AUTOSAR XML (schema 4-1-3)
standard types defined: boolean, sint8, uint16, uint32, uint8, boolean_CompuMethod, boolean_DataConstr, sint8_DataConstr, uint16_DataConstr, uint32_DataConstr, uint8_DataConstr, sint16
package /MICROSAR/Dem_swc/DataTypes
  5 x impl type:
    Dem_DebounceResetStatusType: compu {0=DEM_DEBOUNCE_STATUS_FREEZE, 1=DEM_DEBOUNCE_STATUS_RESET}, range raw 0..255, implementation-data-type=ImplementationDataTypes/uint8
    Dem_DTCFormatType: compu {0=DEM_DTC_FORMAT_OBD, 1=DEM_DTC_FORMAT_UDS, 2=DEM_DTC_FORMAT_J1939}, range raw 0..255, implementation-data-type=ImplementationDataTypes/uint8
    Dem_EventStatusType:
      compu {0=DEM_EVENT_STATUS_PASSED, 1=DEM_EVENT_STATUS_FAILED, 2=DEM_EVENT_STATUS_PREPASSED, 3=DEM_EVENT_STATUS_PREFAILED, 4=DEM_EVENT_STATUS_FDC_THRESHOLD_REACHED, 5=DEM_EVENT_STATUS_PASSED_CONDITIONS_NOT_FULFILLED, 6=DEM_EVENT_STATUS_FAILED_CONDITIONS_NOT_FULFILLED, 7=DEM_EVENT_STATUS_PREPASSED_CONDITIONS_NOT_FULFILLED, 8=DEM_EVENT_STATUS_PREFAILED_CONDITIONS_NOT_FULFILLED}
      range raw 0..255
      implementation-data-type=ImplementationDataTypes/uint8
    Dem_MaxDataValueType: category=ARRAY, sw-calibration-access=READ-ONLY
      element Dem_MaxDataValueTypeElement: array-size=4, array-size-semantics=FIXED-SIZE, implementation-data-type=ImplementationDataTypes/uint8
    Dem_UdsStatusByteType:
      compu {mask 1: 1=DEM_UDS_STATUS_TF (bit 0: TestFailed), mask 2: 2=DEM_UDS_STATUS_TFTOC (bit 1: TestFailedThisOperationCycle), mask 4: 4=DEM_UDS_STATUS_PDTC (bit 2: PendingDTC), mask 8: 8=DEM_UDS_STATUS_CDTC (bit 3: ConfirmedDTC), mask 16: 16=DEM_UDS_STATUS_TNCSLC (bit 4: TestNotCompletedSinceLastClear), mask 32: 32=DEM_UDS_STATUS_TFSLC (bit 5: TestFailedSinceLastClear), mask 64: 64=DEM_UDS_STATUS_TNCTOC (bit 6: TestNotCompletedThisOperationCycle), mask 128: 128=DEM_UDS_STATUS_WIR (bit 7: WarningIndicatorRequested)}
      range raw 0..255
      implementation-data-type=ImplementationDataTypes/uint8
package /MICROSAR/Dem_swc/Interfaces
  client server interface DiagnosticMonitor: is-service=true, service-kind=DIAGNOSTIC-EVENT-MANAGER
    11 x operation:
      GetDTCOfEvent: possible-error=[DEM_E_NO_DTC_AVAILABLE, DiagnosticMonitor/E_NOT_OK]
        arg DTCFormat: type=Dem_DTCFormatType, direction=IN, server-argument-impl-policy=USE-ARGUMENT-TYPE
        arg DTCOfEvent: type=ImplementationDataTypes/uint32, direction=OUT, server-argument-impl-policy=USE-ARGUMENT-TYPE
      GetEventExtendedDataRecordEx: possible-error=[DEM_BUFFER_TOO_SMALL, DEM_NO_SUCH_ELEMENT, DiagnosticMonitor/E_NOT_OK]
        arg RecordNumber: type=ImplementationDataTypes/uint8, direction=IN, server-argument-impl-policy=USE-ARGUMENT-TYPE
        arg DestBuffer: type=Dem_MaxDataValueType, direction=OUT, server-argument-impl-policy=USE-ARGUMENT-TYPE
        arg BufSize: type=ImplementationDataTypes/uint16, direction=INOUT, server-argument-impl-policy=USE-ARGUMENT-TYPE
      GetEventFailed: possible-error=DiagnosticMonitor/E_NOT_OK
        arg EventFailed: type=ImplementationDataTypes/boolean, direction=OUT, server-argument-impl-policy=USE-ARGUMENT-TYPE
      GetEventFreezeFrameDataEx: possible-error=[DEM_BUFFER_TOO_SMALL, DEM_NO_SUCH_ELEMENT, DiagnosticMonitor/E_NOT_OK]
        4 x arg, all with server-argument-impl-policy=USE-ARGUMENT-TYPE:
          RecordNumber: type=ImplementationDataTypes/uint8, direction=IN
          DataId: type=ImplementationDataTypes/uint16, direction=IN
          DestBuffer: type=Dem_MaxDataValueType, direction=OUT
          BufSize: type=ImplementationDataTypes/uint16, direction=INOUT
      GetEventStatus: possible-error=DiagnosticMonitor/E_NOT_OK
        arg UDSStatusByte: type=Dem_UdsStatusByteType, direction=OUT, server-argument-impl-policy=USE-ARGUMENT-TYPE
      GetEventTested: possible-error=DiagnosticMonitor/E_NOT_OK
        arg EventTested: type=ImplementationDataTypes/boolean, direction=OUT, server-argument-impl-policy=USE-ARGUMENT-TYPE
      GetEventUdsStatus: possible-error=DiagnosticMonitor/E_NOT_OK
        arg UDSStatusByte: type=Dem_UdsStatusByteType, direction=OUT, server-argument-impl-policy=USE-ARGUMENT-TYPE
      GetFaultDetectionCounter: possible-error=[DEM_E_NO_FDC_AVAILABLE, DiagnosticMonitor/E_NOT_OK]
        arg FaultDetectionCounter: type=sint8, direction=OUT, server-argument-impl-policy=USE-ARGUMENT-TYPE
      ResetEventDebounceStatus: possible-error=DiagnosticMonitor/E_NOT_OK
        arg DebounceResetStatus: type=Dem_DebounceResetStatusType, direction=IN, server-argument-impl-policy=USE-ARGUMENT-TYPE
      ResetEventStatus: possible-error=DiagnosticMonitor/E_NOT_OK
      SetEventStatus: possible-error=DiagnosticMonitor/E_NOT_OK
        arg EventStatus: type=Dem_EventStatusType, direction=IN, server-argument-impl-policy=USE-ARGUMENT-TYPE
    5 x error:
      DEM_BUFFER_TOO_SMALL: error-code=21
      DEM_E_NO_DTC_AVAILABLE: error-code=10
      DEM_E_NO_FDC_AVAILABLE: error-code=14
      DEM_NO_SUCH_ELEMENT: error-code=48
      E_NOT_OK: error-code=1
package /UAES/ASW/CompuMethods
  compu method CM_boolean: 0=FALSE, 1=TRUE
package /UAES/ASW/DataConstrs
  range DC_boolean: raw 0..1
  range DC_sint16: raw -32768..32767
  range DC_uint16: raw 0..65535
  range DC_uint32: raw 0..4294967295
  range DC_uint8: raw 0..255
package /UAES/ASW/DataTypeMappingSets
  data type mapping set DTMS_Lock_DD
package /UAES/ASW/PortInterfaces
  5 x client server interface:
    IoHwAb_HbrModCtrl
      operation Hbr_SetMod: possible-error=IoHwAb_HbrModCtrl/E_NOT_OK
        arg id_u16: type=ImplementationDataTypes/uint16, direction=IN, server-argument-impl-policy=USE-ARGUMENT-TYPE
        arg mod_u8: type=ImplementationDataTypes/uint8, direction=IN, server-argument-impl-policy=USE-ARGUMENT-TYPE
      error E_NOT_OK: error-code=1
    IoHwAb_HbrPwm
      operation Hbr_SetDuty: possible-error=IoHwAb_HbrPwm/E_NOT_OK
        arg id_u16: type=ImplementationDataTypes/uint16, direction=IN, server-argument-impl-policy=USE-ARGUMENT-TYPE
        arg duty_u16: type=ImplementationDataTypes/uint16, direction=IN, server-argument-impl-policy=USE-ARGUMENT-TYPE
      operation Hbr_SetPerd: possible-error=IoHwAb_HbrPwm/E_NOT_OK
        arg id_u16: type=ImplementationDataTypes/uint16, direction=IN, server-argument-impl-policy=USE-ARGUMENT-TYPE
        arg perd_u32: type=ImplementationDataTypes/uint32, direction=IN, server-argument-impl-policy=USE-ARGUMENT-TYPE
      operation Hbr_SetPerdAndDuty: possible-error=IoHwAb_HbrPwm/E_NOT_OK
        arg id_u16: type=ImplementationDataTypes/uint16, direction=IN, server-argument-impl-policy=USE-ARGUMENT-TYPE
        arg perd_u32: type=ImplementationDataTypes/uint32, direction=IN, server-argument-impl-policy=USE-ARGUMENT-TYPE
        arg duty_u16: type=ImplementationDataTypes/uint16, direction=IN, server-argument-impl-policy=USE-ARGUMENT-TYPE
      error E_NOT_OK: error-code=1
    IoHwAb_IoDiagHbr
      operation Hbr_Get: possible-error=IoHwAb_IoDiagHbr/E_NOT_OK
        arg id_u16: type=ImplementationDataTypes/uint16, direction=IN, server-argument-impl-policy=USE-ARGUMENT-TYPE
        arg val_u32: type=ImplementationDataTypes/uint32, direction=OUT, server-argument-impl-policy=USE-ARGUMENT-TYPE
      error E_NOT_OK: error-code=1
    IoHwAb_IoSigAdc
      operation Adc_Get: possible-error=IoHwAb_IoSigAdc/E_NOT_OK
        arg id_u16: type=ImplementationDataTypes/uint16, direction=IN, server-argument-impl-policy=USE-ARGUMENT-TYPE
        arg val_s16: type=sint16, direction=OUT, server-argument-impl-policy=USE-ARGUMENT-TYPE
      operation AdcFac_Get: possible-error=IoHwAb_IoSigAdc/E_NOT_OK
        arg id_u16: type=ImplementationDataTypes/uint16, direction=IN, server-argument-impl-policy=USE-ARGUMENT-TYPE
        arg val_s16: type=sint16, direction=OUT, server-argument-impl-policy=USE-ARGUMENT-TYPE
      operation AdcVRMBatt_Get: possible-error=IoHwAb_IoSigAdc/E_NOT_OK
        arg id_u16: type=ImplementationDataTypes/uint16, direction=IN, server-argument-impl-policy=USE-ARGUMENT-TYPE
        arg val_u8: type=ImplementationDataTypes/uint8, direction=OUT, server-argument-impl-policy=USE-ARGUMENT-TYPE
      error E_NOT_OK: error-code=1
    IoHwAb_IoSigDio
      operation Di_Get: possible-error=IoHwAb_IoSigDio/E_NOT_OK
        arg id_u16: type=ImplementationDataTypes/uint16, direction=IN, server-argument-impl-policy=USE-ARGUMENT-TYPE
        arg val_u8: type=ImplementationDataTypes/uint8, direction=OUT, server-argument-impl-policy=USE-ARGUMENT-TYPE
      operation Do_Set: possible-error=IoHwAb_IoSigDio/E_NOT_OK
        arg id_u16: type=ImplementationDataTypes/uint16, direction=IN, server-argument-impl-policy=USE-ARGUMENT-TYPE
        arg val_u8: type=ImplementationDataTypes/uint8, direction=IN, server-argument-impl-policy=USE-ARGUMENT-TYPE
      error E_NOT_OK: error-code=1
  62 x sender receiver interface:
    gHoodLock_bLockCmdTrigUds: invalidation-policy{data-element=gHoodLock_bLockCmdTrigUds/Val, handle-invalid=DONT-INVALIDATE}
      data Val: sw-calibration-access=READ-ONLY, type=ImplementationDataTypes/boolean
    gHoodLock_u8LockCmd: invalidation-policy{data-element=gHoodLock_u8LockCmd/Val, handle-invalid=DONT-INVALIDATE}
      data Val: sw-calibration-access=READ-ONLY, type=ImplementationDataTypes/uint8
    gHoodLock_u8LockCmdUds: invalidation-policy{data-element=gHoodLock_u8LockCmdUds/Val, handle-invalid=DONT-INVALIDATE}
      data Val: sw-calibration-access=READ-ONLY, type=ImplementationDataTypes/uint8
    gLock_bChrgCapSwt: invalidation-policy{data-element=gLock_bChrgCapSwt/Val, handle-invalid=DONT-INVALIDATE}
      data Val: sw-calibration-access=READ-ONLY, type=ImplementationDataTypes/boolean
    gLock_bDrvChrgCapUnlockSwt: invalidation-policy{data-element=gLock_bDrvChrgCapUnlockSwt/Val, handle-invalid=DONT-INVALIDATE}
      data Val: sw-calibration-access=READ-ONLY, type=ImplementationDataTypes/boolean
    gLock_bExtTrunkUnlockSwt: invalidation-policy{data-element=gLock_bExtTrunkUnlockSwt/Val, handle-invalid=DONT-INVALIDATE}
      data Val: sw-calibration-access=READ-ONLY, type=ImplementationDataTypes/boolean
    gLock_bFLDoorLockFbSt: invalidation-policy{data-element=gLock_bFLDoorLockFbSt/Val, handle-invalid=DONT-INVALIDATE}
      data Val: sw-calibration-access=READ-ONLY, type=ImplementationDataTypes/boolean
    gLock_bFLPwrRelsMotorMinusSt: invalidation-policy{data-element=gLock_bFLPwrRelsMotorMinusSt/Val, handle-invalid=DONT-INVALIDATE}
      data Val: sw-calibration-access=READ-ONLY, type=ImplementationDataTypes/boolean
    gLock_bFLPwrRelsMotorPlusSt: invalidation-policy{data-element=gLock_bFLPwrRelsMotorPlusSt/Val, handle-invalid=DONT-INVALIDATE}
      data Val: sw-calibration-access=READ-ONLY, type=ImplementationDataTypes/boolean
    gLock_bFRDoorLockFbSt: invalidation-policy{data-element=gLock_bFRDoorLockFbSt/Val, handle-invalid=DONT-INVALIDATE}
      data Val: sw-calibration-access=READ-ONLY, type=ImplementationDataTypes/boolean
    gLock_bFRPwrRelsMotorMinusSt: invalidation-policy{data-element=gLock_bFRPwrRelsMotorMinusSt/Val, handle-invalid=DONT-INVALIDATE}
      data Val: sw-calibration-access=READ-ONLY, type=ImplementationDataTypes/boolean
    gLock_bFRPwrRelsMotorPlusSt: invalidation-policy{data-element=gLock_bFRPwrRelsMotorPlusSt/Val, handle-invalid=DONT-INVALIDATE}
      data Val: sw-calibration-access=READ-ONLY, type=ImplementationDataTypes/boolean
    gLock_bHoodUnlockSwt: invalidation-policy{data-element=gLock_bHoodUnlockSwt/Val, handle-invalid=DONT-INVALIDATE}
      data Val: sw-calibration-access=READ-ONLY, type=ImplementationDataTypes/boolean
    gLock_bIntTrunkUnlockSwt: invalidation-policy{data-element=gLock_bIntTrunkUnlockSwt/Val, handle-invalid=DONT-INVALIDATE}
      data Val: sw-calibration-access=READ-ONLY, type=ImplementationDataTypes/boolean
    gLock_bMasterDrvLockSwt: invalidation-policy{data-element=gLock_bMasterDrvLockSwt/Val, handle-invalid=DONT-INVALIDATE}
      data Val: sw-calibration-access=READ-ONLY, type=ImplementationDataTypes/boolean
    gLock_bMasterLockSwt: invalidation-policy{data-element=gLock_bMasterLockSwt/Val, handle-invalid=DONT-INVALIDATE}
      data Val: sw-calibration-access=READ-ONLY, type=ImplementationDataTypes/boolean
    gLock_bMasterPsgLockSwt: invalidation-policy{data-element=gLock_bMasterPsgLockSwt/Val, handle-invalid=DONT-INVALIDATE}
      data Val: sw-calibration-access=READ-ONLY, type=ImplementationDataTypes/boolean
    gLock_bMasterUnlockSwt: invalidation-policy{data-element=gLock_bMasterUnlockSwt/Val, handle-invalid=DONT-INVALIDATE}
      data Val: sw-calibration-access=READ-ONLY, type=ImplementationDataTypes/boolean
    gLock_bMechKeyLockSwt: invalidation-policy{data-element=gLock_bMechKeyLockSwt/Val, handle-invalid=DONT-INVALIDATE}
      data Val: sw-calibration-access=READ-ONLY, type=ImplementationDataTypes/boolean
    gLock_bMechKeyUnlockSwt: invalidation-policy{data-element=gLock_bMechKeyUnlockSwt/Val, handle-invalid=DONT-INVALIDATE}
      data Val: sw-calibration-access=READ-ONLY, type=ImplementationDataTypes/boolean
    gLock_bRLChildLockFbSt: invalidation-policy{data-element=gLock_bRLChildLockFbSt/Val, handle-invalid=DONT-INVALIDATE}
      data Val: sw-calibration-access=READ-ONLY, type=ImplementationDataTypes/boolean
    gLock_bRLDoorLockFbSt: invalidation-policy{data-element=gLock_bRLDoorLockFbSt/Val, handle-invalid=DONT-INVALIDATE}
      data Val: sw-calibration-access=READ-ONLY, type=ImplementationDataTypes/boolean
    gLock_bRLPwrRelsMotorMinusSt: invalidation-policy{data-element=gLock_bRLPwrRelsMotorMinusSt/Val, handle-invalid=DONT-INVALIDATE}
      data Val: sw-calibration-access=READ-ONLY, type=ImplementationDataTypes/boolean
    gLock_bRLPwrRelsMotorPlusSt: invalidation-policy{data-element=gLock_bRLPwrRelsMotorPlusSt/Val, handle-invalid=DONT-INVALIDATE}
      data Val: sw-calibration-access=READ-ONLY, type=ImplementationDataTypes/boolean
    gLock_bRRChildLockFbSt: invalidation-policy{data-element=gLock_bRRChildLockFbSt/Val, handle-invalid=DONT-INVALIDATE}
      data Val: sw-calibration-access=READ-ONLY, type=ImplementationDataTypes/boolean
    gLock_bRRDoorLockFbSt: invalidation-policy{data-element=gLock_bRRDoorLockFbSt/Val, handle-invalid=DONT-INVALIDATE}
      data Val: sw-calibration-access=READ-ONLY, type=ImplementationDataTypes/boolean
    gLock_bRRPwrRelsMotorMinusSt: invalidation-policy{data-element=gLock_bRRPwrRelsMotorMinusSt/Val, handle-invalid=DONT-INVALIDATE}
      data Val: sw-calibration-access=READ-ONLY, type=ImplementationDataTypes/boolean
    gLock_bRRPwrRelsMotorPlusSt: invalidation-policy{data-element=gLock_bRRPwrRelsMotorPlusSt/Val, handle-invalid=DONT-INVALIDATE}
      data Val: sw-calibration-access=READ-ONLY, type=ImplementationDataTypes/boolean
    gLock_u16ChrgCapPosVolt: invalidation-policy{data-element=gLock_u16ChrgCapPosVolt/Val, handle-invalid=DONT-INVALIDATE}
      data Val: sw-calibration-access=READ-ONLY, type=ImplementationDataTypes/uint16
    gLock_u8BootLockMotorPs: invalidation-policy{data-element=gLock_u8BootLockMotorPs/Val, handle-invalid=DONT-INVALIDATE}
      data Val: sw-calibration-access=READ-ONLY, type=ImplementationDataTypes/uint8
    gLock_u8ChrgCapLockMotorPs: invalidation-policy{data-element=gLock_u8ChrgCapLockMotorPs/Val, handle-invalid=DONT-INVALIDATE}
      data Val: sw-calibration-access=READ-ONLY, type=ImplementationDataTypes/uint8
    gLock_u8DiagEnbCnd: invalidation-policy{data-element=gLock_u8DiagEnbCnd/Val, handle-invalid=DONT-INVALIDATE}
      data Val: sw-calibration-access=READ-ONLY, type=ImplementationDataTypes/uint8
    gLock_u8FLDoorLockMotorPs: invalidation-policy{data-element=gLock_u8FLDoorLockMotorPs/Val, handle-invalid=DONT-INVALIDATE}
      data Val: sw-calibration-access=READ-ONLY, type=ImplementationDataTypes/uint8
    gLock_u8FLPwrRelsMotorPs: invalidation-policy{data-element=gLock_u8FLPwrRelsMotorPs/Val, handle-invalid=DONT-INVALIDATE}
      data Val: sw-calibration-access=READ-ONLY, type=ImplementationDataTypes/uint8
    gLock_u8FRDoorLockMotorPs: invalidation-policy{data-element=gLock_u8FRDoorLockMotorPs/Val, handle-invalid=DONT-INVALIDATE}
      data Val: sw-calibration-access=READ-ONLY, type=ImplementationDataTypes/uint8
    gLock_u8FRPwrRelsMotorPs: invalidation-policy{data-element=gLock_u8FRPwrRelsMotorPs/Val, handle-invalid=DONT-INVALIDATE}
      data Val: sw-calibration-access=READ-ONLY, type=ImplementationDataTypes/uint8
    gLock_u8GlcBoxLockMotorPs: invalidation-policy{data-element=gLock_u8GlcBoxLockMotorPs/Val, handle-invalid=DONT-INVALIDATE}
      data Val: sw-calibration-access=READ-ONLY, type=ImplementationDataTypes/uint8
    gLock_u8OilTankLockMotorPs: invalidation-policy{data-element=gLock_u8OilTankLockMotorPs/Val, handle-invalid=DONT-INVALIDATE}
      data Val: sw-calibration-access=READ-ONLY, type=ImplementationDataTypes/uint8
    gLock_u8RLChildLockMotorPs: invalidation-policy{data-element=gLock_u8RLChildLockMotorPs/Val, handle-invalid=DONT-INVALIDATE}
      data Val: sw-calibration-access=READ-ONLY, type=ImplementationDataTypes/uint8
    gLock_u8RLDoorLockMotorPs: invalidation-policy{data-element=gLock_u8RLDoorLockMotorPs/Val, handle-invalid=DONT-INVALIDATE}
      data Val: sw-calibration-access=READ-ONLY, type=ImplementationDataTypes/uint8
    gLock_u8RLPwrRelsMotorPs: invalidation-policy{data-element=gLock_u8RLPwrRelsMotorPs/Val, handle-invalid=DONT-INVALIDATE}
      data Val: sw-calibration-access=READ-ONLY, type=ImplementationDataTypes/uint8
    gLock_u8RRChildLockMotorPs: invalidation-policy{data-element=gLock_u8RRChildLockMotorPs/Val, handle-invalid=DONT-INVALIDATE}
      data Val: sw-calibration-access=READ-ONLY, type=ImplementationDataTypes/uint8
    gLock_u8RRDoorLockMotorPs: invalidation-policy{data-element=gLock_u8RRDoorLockMotorPs/Val, handle-invalid=DONT-INVALIDATE}
      data Val: sw-calibration-access=READ-ONLY, type=ImplementationDataTypes/uint8
    gLock_u8RRPwrRelsMotorPs: invalidation-policy{data-element=gLock_u8RRPwrRelsMotorPs/Val, handle-invalid=DONT-INVALIDATE}
      data Val: sw-calibration-access=READ-ONLY, type=ImplementationDataTypes/uint8
    gLockCtrl_u8BootLockMotorOutput: invalidation-policy{data-element=gLockCtrl_u8BootLockMotorOutput/Val, handle-invalid=DONT-INVALIDATE}
      data Val: sw-calibration-access=READ-ONLY, type=ImplementationDataTypes/uint8
    gLockCtrl_u8ChrgCapLockMotorOutput: invalidation-policy{data-element=gLockCtrl_u8ChrgCapLockMotorOutput/Val, handle-invalid=DONT-INVALIDATE}
      data Val: sw-calibration-access=READ-ONLY, type=ImplementationDataTypes/uint8
    gLockCtrl_u8ElectcGlvBoxLockMotorOutput: invalidation-policy{data-element=gLockCtrl_u8ElectcGlvBoxLockMotorOutput/Val, handle-invalid=DONT-INVALIDATE}
      data Val: sw-calibration-access=READ-ONLY, type=ImplementationDataTypes/uint8
    gLockCtrl_u8FLDoorElecRelMotorOutput: invalidation-policy{data-element=gLockCtrl_u8FLDoorElecRelMotorOutput/Val, handle-invalid=DONT-INVALIDATE}
      data Val: sw-calibration-access=READ-ONLY, type=ImplementationDataTypes/uint8
    gLockCtrl_u8FLDoorElecRelResetMotorOutput: invalidation-policy{data-element=gLockCtrl_u8FLDoorElecRelResetMotorOutput/Val, handle-invalid=DONT-INVALIDATE}
      data Val: sw-calibration-access=READ-ONLY, type=ImplementationDataTypes/uint8
    gLockCtrl_u8FLDoorLockMotorOutput: invalidation-policy{data-element=gLockCtrl_u8FLDoorLockMotorOutput/Val, handle-invalid=DONT-INVALIDATE}
      data Val: sw-calibration-access=READ-ONLY, type=ImplementationDataTypes/uint8
    gLockCtrl_u8FRDoorLockMotorOutput: invalidation-policy{data-element=gLockCtrl_u8FRDoorLockMotorOutput/Val, handle-invalid=DONT-INVALIDATE}
      data Val: sw-calibration-access=READ-ONLY, type=ImplementationDataTypes/uint8
    gLockCtrl_u8FRElecRelMotorOutput: invalidation-policy{data-element=gLockCtrl_u8FRElecRelMotorOutput/Val, handle-invalid=DONT-INVALIDATE}
      data Val: sw-calibration-access=READ-ONLY, type=ImplementationDataTypes/uint8
    gLockCtrl_u8FRElecRelResetMotorOutput: invalidation-policy{data-element=gLockCtrl_u8FRElecRelResetMotorOutput/Val, handle-invalid=DONT-INVALIDATE}
      data Val: sw-calibration-access=READ-ONLY, type=ImplementationDataTypes/uint8
    gLockCtrl_u8OilTankLockMotorOutput: invalidation-policy{data-element=gLockCtrl_u8OilTankLockMotorOutput/Val, handle-invalid=DONT-INVALIDATE}
      data Val: sw-calibration-access=READ-ONLY, type=ImplementationDataTypes/uint8
    gLockCtrl_u8RLChildLockMotorOutput: invalidation-policy{data-element=gLockCtrl_u8RLChildLockMotorOutput/Val, handle-invalid=DONT-INVALIDATE}
      data Val: sw-calibration-access=READ-ONLY, type=ImplementationDataTypes/uint8
    gLockCtrl_u8RLDoorElecRelMotorOutput: invalidation-policy{data-element=gLockCtrl_u8RLDoorElecRelMotorOutput/Val, handle-invalid=DONT-INVALIDATE}
      data Val: sw-calibration-access=READ-ONLY, type=ImplementationDataTypes/uint8
    gLockCtrl_u8RLDoorElecRelPWMMotorOutput: invalidation-policy{data-element=gLockCtrl_u8RLDoorElecRelPWMMotorOutput/Val, handle-invalid=DONT-INVALIDATE}
      data Val: sw-calibration-access=READ-ONLY, type=ImplementationDataTypes/uint8
    gLockCtrl_u8RLDoorLockMotorOutput: invalidation-policy{data-element=gLockCtrl_u8RLDoorLockMotorOutput/Val, handle-invalid=DONT-INVALIDATE}
      data Val: sw-calibration-access=READ-ONLY, type=ImplementationDataTypes/uint8
    gLockCtrl_u8RRChildLockMotorOutput: invalidation-policy{data-element=gLockCtrl_u8RRChildLockMotorOutput/Val, handle-invalid=DONT-INVALIDATE}
      data Val: sw-calibration-access=READ-ONLY, type=ImplementationDataTypes/uint8
    gLockCtrl_u8RRDoorElecRelMotorOutput: invalidation-policy{data-element=gLockCtrl_u8RRDoorElecRelMotorOutput/Val, handle-invalid=DONT-INVALIDATE}
      data Val: sw-calibration-access=READ-ONLY, type=ImplementationDataTypes/uint8
    gLockCtrl_u8RRDoorElecRelPWMMotorOutput: invalidation-policy{data-element=gLockCtrl_u8RRDoorElecRelPWMMotorOutput/Val, handle-invalid=DONT-INVALIDATE}
      data Val: sw-calibration-access=READ-ONLY, type=ImplementationDataTypes/uint8
    gLockCtrl_u8RRDoorLockMotorOutput: invalidation-policy{data-element=gLockCtrl_u8RRDoorLockMotorOutput/Val, handle-invalid=DONT-INVALIDATE}
      data Val: sw-calibration-access=READ-ONLY, type=ImplementationDataTypes/uint8
package /UAES/ASW/SwComponentTypes
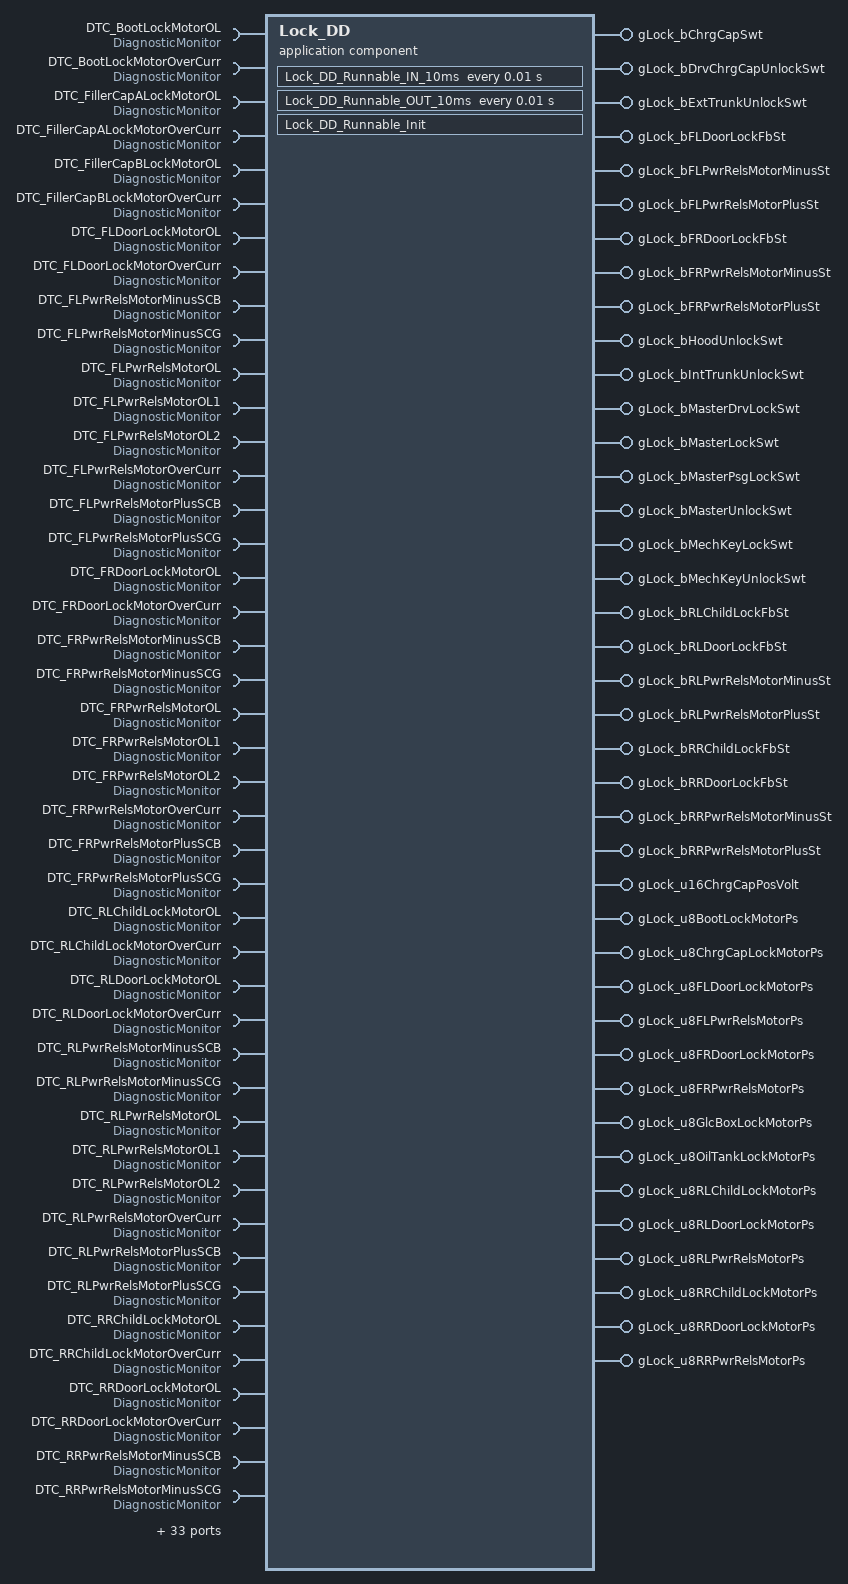
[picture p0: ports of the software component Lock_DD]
  application sw component type Lock_DD
    40 x provide port:
      gLock_bChrgCapSwt: nonqueued-sender-com-spec{data-element=gLock_bChrgCapSwt/Val, init-value=0}, provided-interface=gLock_bChrgCapSwt
      gLock_bDrvChrgCapUnlockSwt: nonqueued-sender-com-spec{data-element=gLock_bDrvChrgCapUnlockSwt/Val, init-value=0}, provided-interface=gLock_bDrvChrgCapUnlockSwt
      gLock_bExtTrunkUnlockSwt: nonqueued-sender-com-spec{data-element=gLock_bExtTrunkUnlockSwt/Val, init-value=0}, provided-interface=gLock_bExtTrunkUnlockSwt
      gLock_bFLDoorLockFbSt: nonqueued-sender-com-spec{data-element=gLock_bFLDoorLockFbSt/Val, init-value=0}, provided-interface=gLock_bFLDoorLockFbSt
      gLock_bFLPwrRelsMotorMinusSt: nonqueued-sender-com-spec{data-element=gLock_bFLPwrRelsMotorMinusSt/Val, init-value=0}, provided-interface=gLock_bFLPwrRelsMotorMinusSt
      gLock_bFLPwrRelsMotorPlusSt: nonqueued-sender-com-spec{data-element=gLock_bFLPwrRelsMotorPlusSt/Val, init-value=0}, provided-interface=gLock_bFLPwrRelsMotorPlusSt
      gLock_bFRDoorLockFbSt: nonqueued-sender-com-spec{data-element=gLock_bFRDoorLockFbSt/Val, init-value=0}, provided-interface=gLock_bFRDoorLockFbSt
      gLock_bFRPwrRelsMotorMinusSt: nonqueued-sender-com-spec{data-element=gLock_bFRPwrRelsMotorMinusSt/Val, init-value=0}, provided-interface=gLock_bFRPwrRelsMotorMinusSt
      gLock_bFRPwrRelsMotorPlusSt: nonqueued-sender-com-spec{data-element=gLock_bFRPwrRelsMotorPlusSt/Val, init-value=0}, provided-interface=gLock_bFRPwrRelsMotorPlusSt
      gLock_bHoodUnlockSwt: nonqueued-sender-com-spec{data-element=gLock_bHoodUnlockSwt/Val, init-value=0}, provided-interface=gLock_bHoodUnlockSwt
      gLock_bIntTrunkUnlockSwt: nonqueued-sender-com-spec{data-element=gLock_bIntTrunkUnlockSwt/Val, init-value=0}, provided-interface=gLock_bIntTrunkUnlockSwt
      gLock_bMasterDrvLockSwt: nonqueued-sender-com-spec{data-element=gLock_bMasterDrvLockSwt/Val, init-value=0}, provided-interface=gLock_bMasterDrvLockSwt
      gLock_bMasterLockSwt: nonqueued-sender-com-spec{data-element=gLock_bMasterLockSwt/Val, init-value=0}, provided-interface=gLock_bMasterLockSwt
      gLock_bMasterPsgLockSwt: nonqueued-sender-com-spec{data-element=gLock_bMasterPsgLockSwt/Val, init-value=0}, provided-interface=gLock_bMasterPsgLockSwt
      gLock_bMasterUnlockSwt: nonqueued-sender-com-spec{data-element=gLock_bMasterUnlockSwt/Val, init-value=0}, provided-interface=gLock_bMasterUnlockSwt
      gLock_bMechKeyLockSwt: nonqueued-sender-com-spec{data-element=gLock_bMechKeyLockSwt/Val, init-value=0}, provided-interface=gLock_bMechKeyLockSwt
      gLock_bMechKeyUnlockSwt: nonqueued-sender-com-spec{data-element=gLock_bMechKeyUnlockSwt/Val, init-value=0}, provided-interface=gLock_bMechKeyUnlockSwt
      gLock_bRLChildLockFbSt: nonqueued-sender-com-spec{data-element=gLock_bRLChildLockFbSt/Val, init-value=0}, provided-interface=gLock_bRLChildLockFbSt
      gLock_bRLDoorLockFbSt: nonqueued-sender-com-spec{data-element=gLock_bRLDoorLockFbSt/Val, init-value=0}, provided-interface=gLock_bRLDoorLockFbSt
      gLock_bRLPwrRelsMotorMinusSt: nonqueued-sender-com-spec{data-element=gLock_bRLPwrRelsMotorMinusSt/Val, init-value=0}, provided-interface=gLock_bRLPwrRelsMotorMinusSt
      gLock_bRLPwrRelsMotorPlusSt: nonqueued-sender-com-spec{data-element=gLock_bRLPwrRelsMotorPlusSt/Val, init-value=0}, provided-interface=gLock_bRLPwrRelsMotorPlusSt
      gLock_bRRChildLockFbSt: nonqueued-sender-com-spec{data-element=gLock_bRRChildLockFbSt/Val, init-value=0}, provided-interface=gLock_bRRChildLockFbSt
      gLock_bRRDoorLockFbSt: nonqueued-sender-com-spec{data-element=gLock_bRRDoorLockFbSt/Val, init-value=0}, provided-interface=gLock_bRRDoorLockFbSt
      gLock_bRRPwrRelsMotorMinusSt: nonqueued-sender-com-spec{data-element=gLock_bRRPwrRelsMotorMinusSt/Val, init-value=0}, provided-interface=gLock_bRRPwrRelsMotorMinusSt
      gLock_bRRPwrRelsMotorPlusSt: nonqueued-sender-com-spec{data-element=gLock_bRRPwrRelsMotorPlusSt/Val, init-value=0}, provided-interface=gLock_bRRPwrRelsMotorPlusSt
      gLock_u16ChrgCapPosVolt: nonqueued-sender-com-spec{data-element=gLock_u16ChrgCapPosVolt/Val, init-value=0}, provided-interface=gLock_u16ChrgCapPosVolt
      gLock_u8BootLockMotorPs: nonqueued-sender-com-spec{data-element=gLock_u8BootLockMotorPs/Val, init-value=0}, provided-interface=gLock_u8BootLockMotorPs
      gLock_u8ChrgCapLockMotorPs: nonqueued-sender-com-spec{data-element=gLock_u8ChrgCapLockMotorPs/Val, init-value=0}, provided-interface=gLock_u8ChrgCapLockMotorPs
      gLock_u8FLDoorLockMotorPs: nonqueued-sender-com-spec{data-element=gLock_u8FLDoorLockMotorPs/Val, init-value=0}, provided-interface=gLock_u8FLDoorLockMotorPs
      gLock_u8FLPwrRelsMotorPs: nonqueued-sender-com-spec{data-element=gLock_u8FLPwrRelsMotorPs/Val, init-value=0}, provided-interface=gLock_u8FLPwrRelsMotorPs
      gLock_u8FRDoorLockMotorPs: nonqueued-sender-com-spec{data-element=gLock_u8FRDoorLockMotorPs/Val, init-value=0}, provided-interface=gLock_u8FRDoorLockMotorPs
      gLock_u8FRPwrRelsMotorPs: nonqueued-sender-com-spec{data-element=gLock_u8FRPwrRelsMotorPs/Val, init-value=0}, provided-interface=gLock_u8FRPwrRelsMotorPs
      gLock_u8GlcBoxLockMotorPs: nonqueued-sender-com-spec{data-element=gLock_u8GlcBoxLockMotorPs/Val, init-value=0}, provided-interface=gLock_u8GlcBoxLockMotorPs
      gLock_u8OilTankLockMotorPs: nonqueued-sender-com-spec{data-element=gLock_u8OilTankLockMotorPs/Val, init-value=0}, provided-interface=gLock_u8OilTankLockMotorPs
      gLock_u8RLChildLockMotorPs: nonqueued-sender-com-spec{data-element=gLock_u8RLChildLockMotorPs/Val, init-value=0}, provided-interface=gLock_u8RLChildLockMotorPs
      gLock_u8RLDoorLockMotorPs: nonqueued-sender-com-spec{data-element=gLock_u8RLDoorLockMotorPs/Val, init-value=0}, provided-interface=gLock_u8RLDoorLockMotorPs
      gLock_u8RLPwrRelsMotorPs: nonqueued-sender-com-spec{data-element=gLock_u8RLPwrRelsMotorPs/Val, init-value=0}, provided-interface=gLock_u8RLPwrRelsMotorPs
      gLock_u8RRChildLockMotorPs: nonqueued-sender-com-spec{data-element=gLock_u8RRChildLockMotorPs/Val, init-value=0}, provided-interface=gLock_u8RRChildLockMotorPs
      gLock_u8RRDoorLockMotorPs: nonqueued-sender-com-spec{data-element=gLock_u8RRDoorLockMotorPs/Val, init-value=0}, provided-interface=gLock_u8RRDoorLockMotorPs
      gLock_u8RRPwrRelsMotorPs: nonqueued-sender-com-spec{data-element=gLock_u8RRPwrRelsMotorPs/Val, init-value=0}, provided-interface=gLock_u8RRPwrRelsMotorPs
    77 x require port:
      DTC_BootLockMotorOL: required-interface=DiagnosticMonitor
        required-com-specs:
          GetDTCOfEvent
          GetEventExtendedDataRecordEx
          GetEventFailed
          GetEventFreezeFrameDataEx
          GetEventStatus
          GetEventTested
          GetEventUdsStatus
          GetFaultDetectionCounter
          ResetEventDebounceStatus
          ResetEventStatus
          SetEventStatus
      DTC_BootLockMotorOverCurr: required-interface=DiagnosticMonitor
        required-com-specs:
          GetDTCOfEvent
          GetEventExtendedDataRecordEx
          GetEventFailed
          GetEventFreezeFrameDataEx
          GetEventStatus
          GetEventTested
          GetEventUdsStatus
          GetFaultDetectionCounter
          ResetEventDebounceStatus
          ResetEventStatus
          SetEventStatus
      DTC_FillerCapALockMotorOL: required-interface=DiagnosticMonitor
        required-com-specs:
          GetDTCOfEvent
          GetEventExtendedDataRecordEx
          GetEventFailed
          GetEventFreezeFrameDataEx
          GetEventStatus
          GetEventTested
          GetEventUdsStatus
          GetFaultDetectionCounter
          ResetEventDebounceStatus
          ResetEventStatus
          SetEventStatus
      DTC_FillerCapALockMotorOverCurr: required-interface=DiagnosticMonitor
        required-com-specs:
          GetDTCOfEvent
          GetEventExtendedDataRecordEx
          GetEventFailed
          GetEventFreezeFrameDataEx
          GetEventStatus
          GetEventTested
          GetEventUdsStatus
          GetFaultDetectionCounter
          ResetEventDebounceStatus
          ResetEventStatus
          SetEventStatus
      DTC_FillerCapBLockMotorOL: required-interface=DiagnosticMonitor
        required-com-specs:
          GetDTCOfEvent
          GetEventExtendedDataRecordEx
          GetEventFailed
          GetEventFreezeFrameDataEx
          GetEventStatus
          GetEventTested
          GetEventUdsStatus
          GetFaultDetectionCounter
          ResetEventDebounceStatus
          ResetEventStatus
          SetEventStatus
      DTC_FillerCapBLockMotorOverCurr: required-interface=DiagnosticMonitor
        required-com-specs:
          GetDTCOfEvent
          GetEventExtendedDataRecordEx
          GetEventFailed
          GetEventFreezeFrameDataEx
          GetEventStatus
          GetEventTested
          GetEventUdsStatus
          GetFaultDetectionCounter
          ResetEventDebounceStatus
          ResetEventStatus
          SetEventStatus
      DTC_FLDoorLockMotorOL: required-interface=DiagnosticMonitor
        required-com-specs:
          GetDTCOfEvent
          GetEventExtendedDataRecordEx
          GetEventFailed
          GetEventFreezeFrameDataEx
          GetEventStatus
          GetEventTested
          GetEventUdsStatus
          GetFaultDetectionCounter
          ResetEventDebounceStatus
          ResetEventStatus
          SetEventStatus
      DTC_FLDoorLockMotorOverCurr: required-interface=DiagnosticMonitor
        required-com-specs:
          GetDTCOfEvent
          GetEventExtendedDataRecordEx
          GetEventFailed
          GetEventFreezeFrameDataEx
          GetEventStatus
          GetEventTested
          GetEventUdsStatus
          GetFaultDetectionCounter
          ResetEventDebounceStatus
          ResetEventStatus
          SetEventStatus
      DTC_FLPwrRelsMotorMinusSCB: required-interface=DiagnosticMonitor
        required-com-specs:
          GetDTCOfEvent
          GetEventExtendedDataRecordEx
          GetEventFailed
          GetEventFreezeFrameDataEx
          GetEventStatus
          GetEventTested
          GetEventUdsStatus
          GetFaultDetectionCounter
          ResetEventDebounceStatus
          ResetEventStatus
          SetEventStatus
      DTC_FLPwrRelsMotorMinusSCG: required-interface=DiagnosticMonitor
        required-com-specs:
          GetDTCOfEvent
          GetEventExtendedDataRecordEx
          GetEventFailed
          GetEventFreezeFrameDataEx
          GetEventStatus
          GetEventTested
          GetEventUdsStatus
          GetFaultDetectionCounter
          ResetEventDebounceStatus
          ResetEventStatus
          SetEventStatus
      DTC_FLPwrRelsMotorOL: required-interface=DiagnosticMonitor
        required-com-specs:
          GetDTCOfEvent
          GetEventExtendedDataRecordEx
          GetEventFailed
          GetEventFreezeFrameDataEx
          GetEventStatus
          GetEventTested
          GetEventUdsStatus
          GetFaultDetectionCounter
          ResetEventDebounceStatus
          ResetEventStatus
          SetEventStatus
      DTC_FLPwrRelsMotorOL1: required-interface=DiagnosticMonitor
        required-com-specs:
          GetDTCOfEvent
          GetEventExtendedDataRecordEx
          GetEventFailed
          GetEventFreezeFrameDataEx
          GetEventStatus
          GetEventTested
          GetEventUdsStatus
          GetFaultDetectionCounter
          ResetEventDebounceStatus
          ResetEventStatus
          SetEventStatus
      DTC_FLPwrRelsMotorOL2: required-interface=DiagnosticMonitor
        required-com-specs:
          GetDTCOfEvent
          GetEventExtendedDataRecordEx
          GetEventFailed
          GetEventFreezeFrameDataEx
          GetEventStatus
          GetEventTested
          GetEventUdsStatus
          GetFaultDetectionCounter
          ResetEventDebounceStatus
          ResetEventStatus
          SetEventStatus
      DTC_FLPwrRelsMotorOverCurr: required-interface=DiagnosticMonitor
        required-com-specs:
          GetDTCOfEvent
          GetEventExtendedDataRecordEx
          GetEventFailed
          GetEventFreezeFrameDataEx
          GetEventStatus
          GetEventTested
          GetEventUdsStatus
          GetFaultDetectionCounter
          ResetEventDebounceStatus
          ResetEventStatus
          SetEventStatus
      DTC_FLPwrRelsMotorPlusSCB: required-interface=DiagnosticMonitor
        required-com-specs:
          GetDTCOfEvent
          GetEventExtendedDataRecordEx
          GetEventFailed
          GetEventFreezeFrameDataEx
          GetEventStatus
          GetEventTested
          GetEventUdsStatus
          GetFaultDetectionCounter
          ResetEventDebounceStatus
          ResetEventStatus
          SetEventStatus
      DTC_FLPwrRelsMotorPlusSCG: required-interface=DiagnosticMonitor
        required-com-specs:
          GetDTCOfEvent
          GetEventExtendedDataRecordEx
          GetEventFailed
          GetEventFreezeFrameDataEx
          GetEventStatus
          GetEventTested
          GetEventUdsStatus
          GetFaultDetectionCounter
          ResetEventDebounceStatus
          ResetEventStatus
          SetEventStatus
      DTC_FRDoorLockMotorOL: required-interface=DiagnosticMonitor
        required-com-specs:
          GetDTCOfEvent
          GetEventExtendedDataRecordEx
          GetEventFailed
          GetEventFreezeFrameDataEx
          GetEventStatus
          GetEventTested
          GetEventUdsStatus
          GetFaultDetectionCounter
          ResetEventDebounceStatus
          ResetEventStatus
          SetEventStatus
      DTC_FRDoorLockMotorOverCurr: required-interface=DiagnosticMonitor
        required-com-specs:
          GetDTCOfEvent
          GetEventExtendedDataRecordEx
          GetEventFailed
          GetEventFreezeFrameDataEx
          GetEventStatus
          GetEventTested
          GetEventUdsStatus
          GetFaultDetectionCounter
          ResetEventDebounceStatus
          ResetEventStatus
          SetEventStatus
      DTC_FRPwrRelsMotorMinusSCB: required-interface=DiagnosticMonitor
        required-com-specs:
          GetDTCOfEvent
          GetEventExtendedDataRecordEx
          GetEventFailed
          GetEventFreezeFrameDataEx
          GetEventStatus
          GetEventTested
          GetEventUdsStatus
          GetFaultDetectionCounter
          ResetEventDebounceStatus
          ResetEventStatus
          SetEventStatus
      DTC_FRPwrRelsMotorMinusSCG: required-interface=DiagnosticMonitor
        required-com-specs:
          GetDTCOfEvent
          GetEventExtendedDataRecordEx
          GetEventFailed
          GetEventFreezeFrameDataEx
          GetEventStatus
          GetEventTested
          GetEventUdsStatus
          GetFaultDetectionCounter
          ResetEventDebounceStatus
          ResetEventStatus
          SetEventStatus
      DTC_FRPwrRelsMotorOL: required-interface=DiagnosticMonitor
        required-com-specs:
          GetDTCOfEvent
          GetEventExtendedDataRecordEx
          GetEventFailed
          GetEventFreezeFrameDataEx
          GetEventStatus
          GetEventTested
          GetEventUdsStatus
          GetFaultDetectionCounter
          ResetEventDebounceStatus
          ResetEventStatus
          SetEventStatus
      DTC_FRPwrRelsMotorOL1: required-interface=DiagnosticMonitor
        required-com-specs:
          GetDTCOfEvent
          GetEventExtendedDataRecordEx
          GetEventFailed
          GetEventFreezeFrameDataEx
          GetEventStatus
          GetEventTested
          GetEventUdsStatus
          GetFaultDetectionCounter
          ResetEventDebounceStatus
          ResetEventStatus
          SetEventStatus
      DTC_FRPwrRelsMotorOL2: required-interface=DiagnosticMonitor
        required-com-specs:
          GetDTCOfEvent
          GetEventExtendedDataRecordEx
          GetEventFailed
          GetEventFreezeFrameDataEx
          GetEventStatus
          GetEventTested
          GetEventUdsStatus
          GetFaultDetectionCounter
          ResetEventDebounceStatus
          ResetEventStatus
          SetEventStatus
      DTC_FRPwrRelsMotorOverCurr: required-interface=DiagnosticMonitor
        required-com-specs:
          GetDTCOfEvent
          GetEventExtendedDataRecordEx
          GetEventFailed
          GetEventFreezeFrameDataEx
          GetEventStatus
          GetEventTested
          GetEventUdsStatus
          GetFaultDetectionCounter
          ResetEventDebounceStatus
          ResetEventStatus
          SetEventStatus
      DTC_FRPwrRelsMotorPlusSCB: required-interface=DiagnosticMonitor
        required-com-specs:
          GetDTCOfEvent
          GetEventExtendedDataRecordEx
          GetEventFailed
          GetEventFreezeFrameDataEx
          GetEventStatus
          GetEventTested
          GetEventUdsStatus
          GetFaultDetectionCounter
          ResetEventDebounceStatus
          ResetEventStatus
          SetEventStatus
      DTC_FRPwrRelsMotorPlusSCG: required-interface=DiagnosticMonitor
        required-com-specs:
          GetDTCOfEvent
          GetEventExtendedDataRecordEx
          GetEventFailed
          GetEventFreezeFrameDataEx
          GetEventStatus
          GetEventTested
          GetEventUdsStatus
          GetFaultDetectionCounter
          ResetEventDebounceStatus
          ResetEventStatus
          SetEventStatus
      DTC_RLChildLockMotorOL: required-interface=DiagnosticMonitor
        required-com-specs:
          GetDTCOfEvent
          GetEventExtendedDataRecordEx
          GetEventFailed
          GetEventFreezeFrameDataEx
          GetEventStatus
          GetEventTested
          GetEventUdsStatus
          GetFaultDetectionCounter
          ResetEventDebounceStatus
          ResetEventStatus
          SetEventStatus
      DTC_RLChildLockMotorOverCurr: required-interface=DiagnosticMonitor
        required-com-specs:
          GetDTCOfEvent
          GetEventExtendedDataRecordEx
          GetEventFailed
          GetEventFreezeFrameDataEx
          GetEventStatus
          GetEventTested
          GetEventUdsStatus
          GetFaultDetectionCounter
          ResetEventDebounceStatus
          ResetEventStatus
          SetEventStatus
      DTC_RLDoorLockMotorOL: required-interface=DiagnosticMonitor
        required-com-specs:
          GetDTCOfEvent
          GetEventExtendedDataRecordEx
          GetEventFailed
          GetEventFreezeFrameDataEx
          GetEventStatus
          GetEventTested
          GetEventUdsStatus
          GetFaultDetectionCounter
          ResetEventDebounceStatus
          ResetEventStatus
          SetEventStatus
      DTC_RLDoorLockMotorOverCurr: required-interface=DiagnosticMonitor
        required-com-specs:
          GetDTCOfEvent
          GetEventExtendedDataRecordEx
          GetEventFailed
          GetEventFreezeFrameDataEx
          GetEventStatus
          GetEventTested
          GetEventUdsStatus
          GetFaultDetectionCounter
          ResetEventDebounceStatus
          ResetEventStatus
          SetEventStatus
      DTC_RLPwrRelsMotorMinusSCB: required-interface=DiagnosticMonitor
        required-com-specs:
          GetDTCOfEvent
          GetEventExtendedDataRecordEx
          GetEventFailed
          GetEventFreezeFrameDataEx
          GetEventStatus
          GetEventTested
          GetEventUdsStatus
          GetFaultDetectionCounter
          ResetEventDebounceStatus
          ResetEventStatus
          SetEventStatus
      DTC_RLPwrRelsMotorMinusSCG: required-interface=DiagnosticMonitor
        required-com-specs:
          GetDTCOfEvent
          GetEventExtendedDataRecordEx
          GetEventFailed
          GetEventFreezeFrameDataEx
          GetEventStatus
          GetEventTested
          GetEventUdsStatus
          GetFaultDetectionCounter
          ResetEventDebounceStatus
          ResetEventStatus
          SetEventStatus
      DTC_RLPwrRelsMotorOL: required-interface=DiagnosticMonitor
        required-com-specs:
          GetDTCOfEvent
          GetEventExtendedDataRecordEx
          GetEventFailed
          GetEventFreezeFrameDataEx
          GetEventStatus
          GetEventTested
          GetEventUdsStatus
          GetFaultDetectionCounter
          ResetEventDebounceStatus
          ResetEventStatus
          SetEventStatus
      DTC_RLPwrRelsMotorOL1: required-interface=DiagnosticMonitor
        required-com-specs:
          GetDTCOfEvent
          GetEventExtendedDataRecordEx
          GetEventFailed
          GetEventFreezeFrameDataEx
          GetEventStatus
          GetEventTested
          GetEventUdsStatus
          GetFaultDetectionCounter
          ResetEventDebounceStatus
          ResetEventStatus
          SetEventStatus
      DTC_RLPwrRelsMotorOL2: required-interface=DiagnosticMonitor
        required-com-specs:
          GetDTCOfEvent
          GetEventExtendedDataRecordEx
          GetEventFailed
          GetEventFreezeFrameDataEx
          GetEventStatus
          GetEventTested
          GetEventUdsStatus
          GetFaultDetectionCounter
          ResetEventDebounceStatus
          ResetEventStatus
          SetEventStatus
      DTC_RLPwrRelsMotorOverCurr: required-interface=DiagnosticMonitor
        required-com-specs:
          GetDTCOfEvent
          GetEventExtendedDataRecordEx
          GetEventFailed
          GetEventFreezeFrameDataEx
          GetEventStatus
          GetEventTested
          GetEventUdsStatus
          GetFaultDetectionCounter
          ResetEventDebounceStatus
          ResetEventStatus
          SetEventStatus
      DTC_RLPwrRelsMotorPlusSCB: required-interface=DiagnosticMonitor
        required-com-specs:
          GetDTCOfEvent
          GetEventExtendedDataRecordEx
          GetEventFailed
          GetEventFreezeFrameDataEx
          GetEventStatus
          GetEventTested
          GetEventUdsStatus
          GetFaultDetectionCounter
          ResetEventDebounceStatus
          ResetEventStatus
          SetEventStatus
      DTC_RLPwrRelsMotorPlusSCG: required-interface=DiagnosticMonitor
        required-com-specs:
          GetDTCOfEvent
          GetEventExtendedDataRecordEx
          GetEventFailed
          GetEventFreezeFrameDataEx
          GetEventStatus
          GetEventTested
          GetEventUdsStatus
          GetFaultDetectionCounter
          ResetEventDebounceStatus
          ResetEventStatus
          SetEventStatus
      DTC_RRChildLockMotorOL: required-interface=DiagnosticMonitor
        required-com-specs:
          GetDTCOfEvent
          GetEventExtendedDataRecordEx
          GetEventFailed
          GetEventFreezeFrameDataEx
          GetEventStatus
          GetEventTested
          GetEventUdsStatus
          GetFaultDetectionCounter
          ResetEventDebounceStatus
          ResetEventStatus
          SetEventStatus
      DTC_RRChildLockMotorOverCurr: required-interface=DiagnosticMonitor
        required-com-specs:
          GetDTCOfEvent
          GetEventExtendedDataRecordEx
          GetEventFailed
          GetEventFreezeFrameDataEx
          GetEventStatus
          GetEventTested
          GetEventUdsStatus
          GetFaultDetectionCounter
          ResetEventDebounceStatus
          ResetEventStatus
          SetEventStatus
      DTC_RRDoorLockMotorOL: required-interface=DiagnosticMonitor
        required-com-specs:
          GetDTCOfEvent
          GetEventExtendedDataRecordEx
          GetEventFailed
          GetEventFreezeFrameDataEx
          GetEventStatus
          GetEventTested
          GetEventUdsStatus
          GetFaultDetectionCounter
          ResetEventDebounceStatus
          ResetEventStatus
          SetEventStatus
      DTC_RRDoorLockMotorOverCurr: required-interface=DiagnosticMonitor
        required-com-specs:
          GetDTCOfEvent
          GetEventExtendedDataRecordEx
          GetEventFailed
          GetEventFreezeFrameDataEx
          GetEventStatus
          GetEventTested
          GetEventUdsStatus
          GetFaultDetectionCounter
          ResetEventDebounceStatus
          ResetEventStatus
          SetEventStatus
      DTC_RRPwrRelsMotorMinusSCB: required-interface=DiagnosticMonitor
        required-com-specs:
          GetDTCOfEvent
          GetEventExtendedDataRecordEx
          GetEventFailed
          GetEventFreezeFrameDataEx
          GetEventStatus
          GetEventTested
          GetEventUdsStatus
          GetFaultDetectionCounter
          ResetEventDebounceStatus
          ResetEventStatus
          SetEventStatus
      DTC_RRPwrRelsMotorMinusSCG: required-interface=DiagnosticMonitor
        required-com-specs:
          GetDTCOfEvent
          GetEventExtendedDataRecordEx
          GetEventFailed
          GetEventFreezeFrameDataEx
          GetEventStatus
          GetEventTested
          GetEventUdsStatus
          GetFaultDetectionCounter
          ResetEventDebounceStatus
          ResetEventStatus
          SetEventStatus
      DTC_RRPwrRelsMotorOL: required-interface=DiagnosticMonitor
        required-com-specs:
          GetDTCOfEvent
          GetEventExtendedDataRecordEx
          GetEventFailed
          GetEventFreezeFrameDataEx
          GetEventStatus
          GetEventTested
          GetEventUdsStatus
          GetFaultDetectionCounter
          ResetEventDebounceStatus
          ResetEventStatus
          SetEventStatus
      DTC_RRPwrRelsMotorOL1: required-interface=DiagnosticMonitor
        required-com-specs:
          GetDTCOfEvent
          GetEventExtendedDataRecordEx
          GetEventFailed
          GetEventFreezeFrameDataEx
          GetEventStatus
          GetEventTested
          GetEventUdsStatus
          GetFaultDetectionCounter
          ResetEventDebounceStatus
          ResetEventStatus
          SetEventStatus
      DTC_RRPwrRelsMotorOL2: required-interface=DiagnosticMonitor
        required-com-specs:
          GetDTCOfEvent
          GetEventExtendedDataRecordEx
          GetEventFailed
          GetEventFreezeFrameDataEx
          GetEventStatus
          GetEventTested
          GetEventUdsStatus
          GetFaultDetectionCounter
          ResetEventDebounceStatus
          ResetEventStatus
          SetEventStatus
      DTC_RRPwrRelsMotorOverCurr: required-interface=DiagnosticMonitor
        required-com-specs:
          GetDTCOfEvent
          GetEventExtendedDataRecordEx
          GetEventFailed
          GetEventFreezeFrameDataEx
          GetEventStatus
          GetEventTested
          GetEventUdsStatus
          GetFaultDetectionCounter
          ResetEventDebounceStatus
          ResetEventStatus
          SetEventStatus
      DTC_RRPwrRelsMotorPlusSCB: required-interface=DiagnosticMonitor
        required-com-specs:
          GetDTCOfEvent
          GetEventExtendedDataRecordEx
          GetEventFailed
          GetEventFreezeFrameDataEx
          GetEventStatus
          GetEventTested
          GetEventUdsStatus
          GetFaultDetectionCounter
          ResetEventDebounceStatus
          ResetEventStatus
          SetEventStatus
      DTC_RRPwrRelsMotorPlusSCG: required-interface=DiagnosticMonitor
        required-com-specs:
          GetDTCOfEvent
          GetEventExtendedDataRecordEx
          GetEventFailed
          GetEventFreezeFrameDataEx
          GetEventStatus
          GetEventTested
          GetEventUdsStatus
          GetFaultDetectionCounter
          ResetEventDebounceStatus
          ResetEventStatus
          SetEventStatus
      gHoodLock_bLockCmdTrigUds: nonqueued-receiver-com-spec{data-element=gHoodLock_bLockCmdTrigUds/Val, filter=data-filter-type=ALWAYS, init-value=0}, required-interface=gHoodLock_bLockCmdTrigUds
      gHoodLock_u8LockCmd: nonqueued-receiver-com-spec{data-element=gHoodLock_u8LockCmd/Val, filter=data-filter-type=ALWAYS, init-value=0}, required-interface=gHoodLock_u8LockCmd
      gHoodLock_u8LockCmdUds: nonqueued-receiver-com-spec{data-element=gHoodLock_u8LockCmdUds/Val, filter=data-filter-type=ALWAYS, init-value=0}, required-interface=gHoodLock_u8LockCmdUds
      gLock_u8DiagEnbCnd: nonqueued-receiver-com-spec{data-element=gLock_u8DiagEnbCnd/Val, filter=data-filter-type=ALWAYS, init-value=0}, required-interface=gLock_u8DiagEnbCnd
      gLockCtrl_u8BootLockMotorOutput: nonqueued-receiver-com-spec{data-element=gLockCtrl_u8BootLockMotorOutput/Val, filter=data-filter-type=ALWAYS, init-value=0}, required-interface=gLockCtrl_u8BootLockMotorOutput
      gLockCtrl_u8ChrgCapLockMotorOutput: nonqueued-receiver-com-spec{data-element=gLockCtrl_u8ChrgCapLockMotorOutput/Val, filter=data-filter-type=ALWAYS, init-value=0}, required-interface=gLockCtrl_u8ChrgCapLockMotorOutput
      gLockCtrl_u8ElectcGlvBoxLockMotorOutput: nonqueued-receiver-com-spec{data-element=gLockCtrl_u8ElectcGlvBoxLockMotorOutput/Val, filter=data-filter-type=ALWAYS, init-value=0}, required-interface=gLockCtrl_u8ElectcGlvBoxLockMotorOutput
      gLockCtrl_u8FLDoorElecRelMotorOutput: nonqueued-receiver-com-spec{data-element=gLockCtrl_u8FLDoorElecRelMotorOutput/Val, filter=data-filter-type=ALWAYS, init-value=0}, required-interface=gLockCtrl_u8FLDoorElecRelMotorOutput
      gLockCtrl_u8FLDoorElecRelResetMotorOutput: nonqueued-receiver-com-spec{data-element=gLockCtrl_u8FLDoorElecRelResetMotorOutput/Val, filter=data-filter-type=ALWAYS, init-value=0}, required-interface=gLockCtrl_u8FLDoorElecRelResetMotorOutput
      gLockCtrl_u8FLDoorLockMotorOutput: nonqueued-receiver-com-spec{data-element=gLockCtrl_u8FLDoorLockMotorOutput/Val, filter=data-filter-type=ALWAYS, init-value=0}, required-interface=gLockCtrl_u8FLDoorLockMotorOutput
      gLockCtrl_u8FRDoorLockMotorOutput: nonqueued-receiver-com-spec{data-element=gLockCtrl_u8FRDoorLockMotorOutput/Val, filter=data-filter-type=ALWAYS, init-value=0}, required-interface=gLockCtrl_u8FRDoorLockMotorOutput
      gLockCtrl_u8FRElecRelMotorOutput: nonqueued-receiver-com-spec{data-element=gLockCtrl_u8FRElecRelMotorOutput/Val, filter=data-filter-type=ALWAYS, init-value=0}, required-interface=gLockCtrl_u8FRElecRelMotorOutput
      gLockCtrl_u8FRElecRelResetMotorOutput: nonqueued-receiver-com-spec{data-element=gLockCtrl_u8FRElecRelResetMotorOutput/Val, filter=data-filter-type=ALWAYS, init-value=0}, required-interface=gLockCtrl_u8FRElecRelResetMotorOutput
      gLockCtrl_u8OilTankLockMotorOutput: nonqueued-receiver-com-spec{data-element=gLockCtrl_u8OilTankLockMotorOutput/Val, filter=data-filter-type=ALWAYS, init-value=0}, required-interface=gLockCtrl_u8OilTankLockMotorOutput
      gLockCtrl_u8RLChildLockMotorOutput: nonqueued-receiver-com-spec{data-element=gLockCtrl_u8RLChildLockMotorOutput/Val, filter=data-filter-type=ALWAYS, init-value=0}, required-interface=gLockCtrl_u8RLChildLockMotorOutput
      gLockCtrl_u8RLDoorElecRelMotorOutput: nonqueued-receiver-com-spec{data-element=gLockCtrl_u8RLDoorElecRelMotorOutput/Val, filter=data-filter-type=ALWAYS, init-value=0}, required-interface=gLockCtrl_u8RLDoorElecRelMotorOutput
      gLockCtrl_u8RLDoorElecRelPWMMotorOutput: nonqueued-receiver-com-spec{data-element=gLockCtrl_u8RLDoorElecRelPWMMotorOutput/Val, filter=data-filter-type=ALWAYS, init-value=0}, required-interface=gLockCtrl_u8RLDoorElecRelPWMMotorOutput
      gLockCtrl_u8RLDoorLockMotorOutput: nonqueued-receiver-com-spec{data-element=gLockCtrl_u8RLDoorLockMotorOutput/Val, filter=data-filter-type=ALWAYS, init-value=0}, required-interface=gLockCtrl_u8RLDoorLockMotorOutput
      gLockCtrl_u8RRChildLockMotorOutput: nonqueued-receiver-com-spec{data-element=gLockCtrl_u8RRChildLockMotorOutput/Val, filter=data-filter-type=ALWAYS, init-value=0}, required-interface=gLockCtrl_u8RRChildLockMotorOutput
      gLockCtrl_u8RRDoorElecRelMotorOutput: nonqueued-receiver-com-spec{data-element=gLockCtrl_u8RRDoorElecRelMotorOutput/Val, filter=data-filter-type=ALWAYS, init-value=0}, required-interface=gLockCtrl_u8RRDoorElecRelMotorOutput
      gLockCtrl_u8RRDoorElecRelPWMMotorOutput: nonqueued-receiver-com-spec{data-element=gLockCtrl_u8RRDoorElecRelPWMMotorOutput/Val, filter=data-filter-type=ALWAYS, init-value=0}, required-interface=gLockCtrl_u8RRDoorElecRelPWMMotorOutput
      gLockCtrl_u8RRDoorLockMotorOutput: nonqueued-receiver-com-spec{data-element=gLockCtrl_u8RRDoorLockMotorOutput/Val, filter=data-filter-type=ALWAYS, init-value=0}, required-interface=gLockCtrl_u8RRDoorLockMotorOutput
      IoHwAb_HbrModCtrl: client-com-spec=Hbr_SetMod, required-interface=IoHwAb_HbrModCtrl
      IoHwAb_HbrPwm: required-com-specs=[Hbr_SetDuty, Hbr_SetPerd, Hbr_SetPerdAndDuty], required-interface=IoHwAb_HbrPwm
      IoHwAb_IoDiagHbr: client-com-spec=Hbr_Get, required-interface=IoHwAb_IoDiagHbr
      IoHwAb_IoSigAdc: required-com-specs=[Adc_Get, AdcFac_Get, AdcVRMBatt_Get], required-interface=IoHwAb_IoSigAdc
      IoHwAb_IoSigDio: required-com-specs=[Di_Get, Do_Set], required-interface=IoHwAb_IoSigDio
    behavior Lock_DD_InternalBehavior: data-type-mapping=DTMS_Lock_DD
      timing event TMT_Lock_DD_Runnable_IN_10ms: start-on-event=Lock_DD_Runnable_IN_10ms, period=0.01
      init event Lock_DD_InitEvent: start-on-event=Lock_DD_Runnable_Init
      timing event TMT_Lock_DD_Runnable_OUT_10ms: start-on-event=Lock_DD_Runnable_OUT_10ms, period=0.01
      runnable Lock_DD_Runnable_IN_10ms
        data-send-points:
          18 x access:
            SEND_gLock_bChrgCapSwt_Val: accessed-variable=gLock_bChrgCapSwt.Val
            SEND_gLock_bDrvChrgCapUnlockSwt_Val: accessed-variable=gLock_bDrvChrgCapUnlockSwt.Val
            SEND_gLock_bExtTrunkUnlockSwt_Val: accessed-variable=gLock_bExtTrunkUnlockSwt.Val
            SEND_gLock_bFLDoorLockFbSt_Val: accessed-variable=gLock_bFLDoorLockFbSt.Val
            SEND_gLock_bFRDoorLockFbSt_Val: accessed-variable=gLock_bFRDoorLockFbSt.Val
            SEND_gLock_bHoodUnlockSwt_Val: accessed-variable=gLock_bHoodUnlockSwt.Val
            SEND_gLock_bIntTrunkUnlockSwt_Val: accessed-variable=gLock_bIntTrunkUnlockSwt.Val
            SEND_gLock_bMasterDrvLockSwt_Val: accessed-variable=gLock_bMasterDrvLockSwt.Val
            SEND_gLock_bMasterLockSwt_Val: accessed-variable=gLock_bMasterLockSwt.Val
            SEND_gLock_bMasterPsgLockSwt_Val: accessed-variable=gLock_bMasterPsgLockSwt.Val
            SEND_gLock_bMasterUnlockSwt_Val: accessed-variable=gLock_bMasterUnlockSwt.Val
            SEND_gLock_bMechKeyLockSwt_Val: accessed-variable=gLock_bMechKeyLockSwt.Val
            SEND_gLock_bMechKeyUnlockSwt_Val: accessed-variable=gLock_bMechKeyUnlockSwt.Val
            SEND_gLock_bRLChildLockFbSt_Val: accessed-variable=gLock_bRLChildLockFbSt.Val
            SEND_gLock_bRLDoorLockFbSt_Val: accessed-variable=gLock_bRLDoorLockFbSt.Val
            SEND_gLock_bRRChildLockFbSt_Val: accessed-variable=gLock_bRRChildLockFbSt.Val
            SEND_gLock_bRRDoorLockFbSt_Val: accessed-variable=gLock_bRRDoorLockFbSt.Val
            SEND_gLock_u16ChrgCapPosVolt_Val: accessed-variable=gLock_u16ChrgCapPosVolt.Val
        sync call SC_IoHwAb_IoSigAdc_AdcFac_Get: operation=IoHwAb_IoSigAdc.AdcFac_Get, timeout=0
        sync call SC_IoHwAb_IoSigDio_Di_Get: operation=IoHwAb_IoSigDio.Di_Get, timeout=0
      runnable Lock_DD_Runnable_Init
      runnable Lock_DD_Runnable_OUT_10ms
        data-receive-point-by-arguments:
          22 x access:
            REC_gHoodLock_bLockCmdTrigUds_Val: accessed-variable=gHoodLock_bLockCmdTrigUds.Val
            REC_gHoodLock_u8LockCmd_Val: accessed-variable=gHoodLock_u8LockCmd.Val
            REC_gHoodLock_u8LockCmdUds_Val: accessed-variable=gHoodLock_u8LockCmdUds.Val
            REC_gLock_u8DiagEnbCnd_Val: accessed-variable=gLock_u8DiagEnbCnd.Val
            REC_gLockCtrl_u8BootLockMotorOutput_Val: accessed-variable=gLockCtrl_u8BootLockMotorOutput.Val
            REC_gLockCtrl_u8ChrgCapLockMotorOutput_Val: accessed-variable=gLockCtrl_u8ChrgCapLockMotorOutput.Val
            REC_gLockCtrl_u8ElectcGlvBoxLockMotorOutput_Val: accessed-variable=gLockCtrl_u8ElectcGlvBoxLockMotorOutput.Val
            REC_gLockCtrl_u8FLDoorElecRelMotorOutput_Val: accessed-variable=gLockCtrl_u8FLDoorElecRelMotorOutput.Val
            REC_gLockCtrl_u8FLDoorElecRelResetMotorOutput_Val: accessed-variable=gLockCtrl_u8FLDoorElecRelResetMotorOutput.Val
            REC_gLockCtrl_u8FLDoorLockMotorOutput_Val: accessed-variable=gLockCtrl_u8FLDoorLockMotorOutput.Val
            REC_gLockCtrl_u8FRDoorLockMotorOutput_Val: accessed-variable=gLockCtrl_u8FRDoorLockMotorOutput.Val
            REC_gLockCtrl_u8FRElecRelMotorOutput_Val: accessed-variable=gLockCtrl_u8FRElecRelMotorOutput.Val
            REC_gLockCtrl_u8FRElecRelResetMotorOutput_Val: accessed-variable=gLockCtrl_u8FRElecRelResetMotorOutput.Val
            REC_gLockCtrl_u8OilTankLockMotorOutput_Val: accessed-variable=gLockCtrl_u8OilTankLockMotorOutput.Val
            REC_gLockCtrl_u8RLChildLockMotorOutput_Val: accessed-variable=gLockCtrl_u8RLChildLockMotorOutput.Val
            REC_gLockCtrl_u8RLDoorElecRelMotorOutput_Val: accessed-variable=gLockCtrl_u8RLDoorElecRelMotorOutput.Val
            REC_gLockCtrl_u8RLDoorElecRelPWMMotorOutput_Val: accessed-variable=gLockCtrl_u8RLDoorElecRelPWMMotorOutput.Val
            REC_gLockCtrl_u8RLDoorLockMotorOutput_Val: accessed-variable=gLockCtrl_u8RLDoorLockMotorOutput.Val
            REC_gLockCtrl_u8RRChildLockMotorOutput_Val: accessed-variable=gLockCtrl_u8RRChildLockMotorOutput.Val
            REC_gLockCtrl_u8RRDoorElecRelMotorOutput_Val: accessed-variable=gLockCtrl_u8RRDoorElecRelMotorOutput.Val
            REC_gLockCtrl_u8RRDoorElecRelPWMMotorOutput_Val: accessed-variable=gLockCtrl_u8RRDoorElecRelPWMMotorOutput.Val
            REC_gLockCtrl_u8RRDoorLockMotorOutput_Val: accessed-variable=gLockCtrl_u8RRDoorLockMotorOutput.Val
        data-send-points:
          22 x access:
            SEND_gLock_bFLPwrRelsMotorMinusSt_Val: accessed-variable=gLock_bFLPwrRelsMotorMinusSt.Val
            SEND_gLock_bFLPwrRelsMotorPlusSt_Val: accessed-variable=gLock_bFLPwrRelsMotorPlusSt.Val
            SEND_gLock_bFRPwrRelsMotorMinusSt_Val: accessed-variable=gLock_bFRPwrRelsMotorMinusSt.Val
            SEND_gLock_bFRPwrRelsMotorPlusSt_Val: accessed-variable=gLock_bFRPwrRelsMotorPlusSt.Val
            SEND_gLock_bRLPwrRelsMotorMinusSt_Val: accessed-variable=gLock_bRLPwrRelsMotorMinusSt.Val
            SEND_gLock_bRLPwrRelsMotorPlusSt_Val: accessed-variable=gLock_bRLPwrRelsMotorPlusSt.Val
            SEND_gLock_bRRPwrRelsMotorMinusSt_Val: accessed-variable=gLock_bRRPwrRelsMotorMinusSt.Val
            SEND_gLock_bRRPwrRelsMotorPlusSt_Val: accessed-variable=gLock_bRRPwrRelsMotorPlusSt.Val
            SEND_gLock_u8BootLockMotorPs_Val: accessed-variable=gLock_u8BootLockMotorPs.Val
            SEND_gLock_u8ChrgCapLockMotorPs_Val: accessed-variable=gLock_u8ChrgCapLockMotorPs.Val
            SEND_gLock_u8FLDoorLockMotorPs_Val: accessed-variable=gLock_u8FLDoorLockMotorPs.Val
            SEND_gLock_u8FLPwrRelsMotorPs_Val: accessed-variable=gLock_u8FLPwrRelsMotorPs.Val
            SEND_gLock_u8FRDoorLockMotorPs_Val: accessed-variable=gLock_u8FRDoorLockMotorPs.Val
            SEND_gLock_u8FRPwrRelsMotorPs_Val: accessed-variable=gLock_u8FRPwrRelsMotorPs.Val
            SEND_gLock_u8GlcBoxLockMotorPs_Val: accessed-variable=gLock_u8GlcBoxLockMotorPs.Val
            SEND_gLock_u8OilTankLockMotorPs_Val: accessed-variable=gLock_u8OilTankLockMotorPs.Val
            SEND_gLock_u8RLChildLockMotorPs_Val: accessed-variable=gLock_u8RLChildLockMotorPs.Val
            SEND_gLock_u8RLDoorLockMotorPs_Val: accessed-variable=gLock_u8RLDoorLockMotorPs.Val
            SEND_gLock_u8RLPwrRelsMotorPs_Val: accessed-variable=gLock_u8RLPwrRelsMotorPs.Val
            SEND_gLock_u8RRChildLockMotorPs_Val: accessed-variable=gLock_u8RRChildLockMotorPs.Val
            SEND_gLock_u8RRDoorLockMotorPs_Val: accessed-variable=gLock_u8RRDoorLockMotorPs.Val
            SEND_gLock_u8RRPwrRelsMotorPs_Val: accessed-variable=gLock_u8RRPwrRelsMotorPs.Val
        153 x sync call:
          SC_DTC_BootLockMotorOL_GetEventFailed: operation=DTC_BootLockMotorOL.GetEventFailed, timeout=1E-06
          SC_DTC_BootLockMotorOL_ResetEventDebounceStatus: operation=DTC_BootLockMotorOL.ResetEventDebounceStatus, timeout=1E-06
          SC_DTC_BootLockMotorOL_SetEventStatus: operation=DTC_BootLockMotorOL.SetEventStatus, timeout=1E-06
          SC_DTC_BootLockMotorOverCurr_GetEventFailed: operation=DTC_BootLockMotorOverCurr.GetEventFailed, timeout=1E-06
          SC_DTC_BootLockMotorOverCurr_ResetEventDebounceStatus: operation=DTC_BootLockMotorOverCurr.ResetEventDebounceStatus, timeout=1E-06
          SC_DTC_BootLockMotorOverCurr_SetEventStatus: operation=DTC_BootLockMotorOverCurr.SetEventStatus, timeout=1E-06
          SC_DTC_FillerCapALockMotorOL_GetEventFailed: operation=DTC_FillerCapALockMotorOL.GetEventFailed, timeout=1E-06
          SC_DTC_FillerCapALockMotorOL_ResetEventDebounceStatus: operation=DTC_FillerCapALockMotorOL.ResetEventDebounceStatus, timeout=1E-06
          SC_DTC_FillerCapALockMotorOL_SetEventStatus: operation=DTC_FillerCapALockMotorOL.SetEventStatus, timeout=1E-06
          SC_DTC_FillerCapALockMotorOverCurr_GetEventFailed: operation=DTC_FillerCapALockMotorOverCurr.GetEventFailed, timeout=1E-06
          SC_DTC_FillerCapALockMotorOverCurr_ResetEventDebounceStatus: operation=DTC_FillerCapALockMotorOverCurr.ResetEventDebounceStatus, timeout=1E-06
          SC_DTC_FillerCapALockMotorOverCurr_SetEventStatus: operation=DTC_FillerCapALockMotorOverCurr.SetEventStatus, timeout=1E-06
          SC_DTC_FillerCapBLockMotorOL_GetEventFailed: operation=DTC_FillerCapBLockMotorOL.GetEventFailed, timeout=1E-06
          SC_DTC_FillerCapBLockMotorOL_ResetEventDebounceStatus: operation=DTC_FillerCapBLockMotorOL.ResetEventDebounceStatus, timeout=1E-06
          SC_DTC_FillerCapBLockMotorOL_SetEventStatus: operation=DTC_FillerCapBLockMotorOL.SetEventStatus, timeout=1E-06
          SC_DTC_FillerCapBLockMotorOverCurr_GetEventFailed: operation=DTC_FillerCapBLockMotorOverCurr.GetEventFailed, timeout=1E-06
          SC_DTC_FillerCapBLockMotorOverCurr_ResetEventDebounceStatus: operation=DTC_FillerCapBLockMotorOverCurr.ResetEventDebounceStatus, timeout=1E-06
          SC_DTC_FillerCapBLockMotorOverCurr_SetEventStatus: operation=DTC_FillerCapBLockMotorOverCurr.SetEventStatus, timeout=1E-06
          SC_DTC_FLDoorLockMotorOL_GetEventFailed: operation=DTC_FLDoorLockMotorOL.GetEventFailed, timeout=1E-06
          SC_DTC_FLDoorLockMotorOL_ResetEventDebounceStatus: operation=DTC_FLDoorLockMotorOL.ResetEventDebounceStatus, timeout=1E-06
          SC_DTC_FLDoorLockMotorOL_SetEventStatus: operation=DTC_FLDoorLockMotorOL.SetEventStatus, timeout=1E-06
          SC_DTC_FLDoorLockMotorOverCurr_GetEventFailed: operation=DTC_FLDoorLockMotorOverCurr.GetEventFailed, timeout=1E-06
          SC_DTC_FLDoorLockMotorOverCurr_ResetEventDebounceStatus: operation=DTC_FLDoorLockMotorOverCurr.ResetEventDebounceStatus, timeout=1E-06
          SC_DTC_FLDoorLockMotorOverCurr_SetEventStatus: operation=DTC_FLDoorLockMotorOverCurr.SetEventStatus, timeout=1E-06
          SC_DTC_FLPwrRelsMotorMinusSCB_GetEventFailed: operation=DTC_FLPwrRelsMotorMinusSCB.GetEventFailed, timeout=1E-06
          SC_DTC_FLPwrRelsMotorMinusSCB_ResetEventDebounceStatus: operation=DTC_FLPwrRelsMotorMinusSCB.ResetEventDebounceStatus, timeout=1E-06
          SC_DTC_FLPwrRelsMotorMinusSCB_SetEventStatus: operation=DTC_FLPwrRelsMotorMinusSCB.SetEventStatus, timeout=1E-06
          SC_DTC_FLPwrRelsMotorMinusSCG_GetEventFailed: operation=DTC_FLPwrRelsMotorMinusSCG.GetEventFailed, timeout=1E-06
          SC_DTC_FLPwrRelsMotorMinusSCG_ResetEventDebounceStatus: operation=DTC_FLPwrRelsMotorMinusSCG.ResetEventDebounceStatus, timeout=1E-06
          SC_DTC_FLPwrRelsMotorMinusSCG_SetEventStatus: operation=DTC_FLPwrRelsMotorMinusSCG.SetEventStatus, timeout=1E-06
          SC_DTC_FLPwrRelsMotorOL_GetEventFailed: operation=DTC_FLPwrRelsMotorOL.GetEventFailed, timeout=1E-06
          SC_DTC_FLPwrRelsMotorOL_ResetEventDebounceStatus: operation=DTC_FLPwrRelsMotorOL.ResetEventDebounceStatus, timeout=1E-06
          SC_DTC_FLPwrRelsMotorOL_SetEventStatus: operation=DTC_FLPwrRelsMotorOL.SetEventStatus, timeout=1E-06
          SC_DTC_FLPwrRelsMotorOL1_GetEventFailed: operation=DTC_FLPwrRelsMotorOL1.GetEventFailed, timeout=1E-06
          SC_DTC_FLPwrRelsMotorOL1_ResetEventDebounceStatus: operation=DTC_FLPwrRelsMotorOL1.ResetEventDebounceStatus, timeout=1E-06
          SC_DTC_FLPwrRelsMotorOL1_SetEventStatus: operation=DTC_FLPwrRelsMotorOL1.SetEventStatus, timeout=1E-06
          SC_DTC_FLPwrRelsMotorOL2_GetEventFailed: operation=DTC_FLPwrRelsMotorOL2.GetEventFailed, timeout=1E-06
          SC_DTC_FLPwrRelsMotorOL2_ResetEventDebounceStatus: operation=DTC_FLPwrRelsMotorOL2.ResetEventDebounceStatus, timeout=1E-06
          SC_DTC_FLPwrRelsMotorOL2_SetEventStatus: operation=DTC_FLPwrRelsMotorOL2.SetEventStatus, timeout=1E-06
          SC_DTC_FLPwrRelsMotorOverCurr_GetEventFailed: operation=DTC_FLPwrRelsMotorOverCurr.GetEventFailed, timeout=1E-06
          SC_DTC_FLPwrRelsMotorOverCurr_ResetEventDebounceStatus: operation=DTC_FLPwrRelsMotorOverCurr.ResetEventDebounceStatus, timeout=1E-06
          SC_DTC_FLPwrRelsMotorOverCurr_SetEventStatus: operation=DTC_FLPwrRelsMotorOverCurr.SetEventStatus, timeout=1E-06
          SC_DTC_FLPwrRelsMotorPlusSCB_GetEventFailed: operation=DTC_FLPwrRelsMotorPlusSCB.GetEventFailed, timeout=1E-06
          SC_DTC_FLPwrRelsMotorPlusSCB_ResetEventDebounceStatus: operation=DTC_FLPwrRelsMotorPlusSCB.ResetEventDebounceStatus, timeout=1E-06
          SC_DTC_FLPwrRelsMotorPlusSCB_SetEventStatus: operation=DTC_FLPwrRelsMotorPlusSCB.SetEventStatus, timeout=1E-06
          SC_DTC_FLPwrRelsMotorPlusSCG_GetEventFailed: operation=DTC_FLPwrRelsMotorPlusSCG.GetEventFailed, timeout=1E-06
          SC_DTC_FLPwrRelsMotorPlusSCG_ResetEventDebounceStatus: operation=DTC_FLPwrRelsMotorPlusSCG.ResetEventDebounceStatus, timeout=1E-06
          SC_DTC_FLPwrRelsMotorPlusSCG_SetEventStatus: operation=DTC_FLPwrRelsMotorPlusSCG.SetEventStatus, timeout=1E-06
          SC_DTC_FRDoorLockMotorOL_GetEventFailed: operation=DTC_FRDoorLockMotorOL.GetEventFailed, timeout=1E-06
          SC_DTC_FRDoorLockMotorOL_ResetEventDebounceStatus: operation=DTC_FRDoorLockMotorOL.ResetEventDebounceStatus, timeout=1E-06
          SC_DTC_FRDoorLockMotorOL_SetEventStatus: operation=DTC_FRDoorLockMotorOL.SetEventStatus, timeout=1E-06
          SC_DTC_FRDoorLockMotorOverCurr_GetEventFailed: operation=DTC_FRDoorLockMotorOverCurr.GetEventFailed, timeout=1E-06
          SC_DTC_FRDoorLockMotorOverCurr_ResetEventDebounceStatus: operation=DTC_FRDoorLockMotorOverCurr.ResetEventDebounceStatus, timeout=1E-06
          SC_DTC_FRDoorLockMotorOverCurr_SetEventStatus: operation=DTC_FRDoorLockMotorOverCurr.SetEventStatus, timeout=1E-06
          SC_DTC_FRPwrRelsMotorMinusSCB_GetEventFailed: operation=DTC_FRPwrRelsMotorMinusSCB.GetEventFailed, timeout=1E-06
          SC_DTC_FRPwrRelsMotorMinusSCB_ResetEventDebounceStatus: operation=DTC_FRPwrRelsMotorMinusSCB.ResetEventDebounceStatus, timeout=1E-06
          SC_DTC_FRPwrRelsMotorMinusSCB_SetEventStatus: operation=DTC_FRPwrRelsMotorMinusSCB.SetEventStatus, timeout=1E-06
          SC_DTC_FRPwrRelsMotorMinusSCG_GetEventFailed: operation=DTC_FRPwrRelsMotorMinusSCG.GetEventFailed, timeout=1E-06
          SC_DTC_FRPwrRelsMotorMinusSCG_ResetEventDebounceStatus: operation=DTC_FRPwrRelsMotorMinusSCG.ResetEventDebounceStatus, timeout=1E-06
          SC_DTC_FRPwrRelsMotorMinusSCG_SetEventStatus: operation=DTC_FRPwrRelsMotorMinusSCG.SetEventStatus, timeout=1E-06
          SC_DTC_FRPwrRelsMotorOL_GetEventFailed: operation=DTC_FRPwrRelsMotorOL.GetEventFailed, timeout=1E-06
          SC_DTC_FRPwrRelsMotorOL_ResetEventDebounceStatus: operation=DTC_FRPwrRelsMotorOL.ResetEventDebounceStatus, timeout=1E-06
          SC_DTC_FRPwrRelsMotorOL_SetEventStatus: operation=DTC_FRPwrRelsMotorOL.SetEventStatus, timeout=1E-06
          SC_DTC_FRPwrRelsMotorOL1_GetEventFailed: operation=DTC_FRPwrRelsMotorOL1.GetEventFailed, timeout=1E-06
          SC_DTC_FRPwrRelsMotorOL1_ResetEventDebounceStatus: operation=DTC_FRPwrRelsMotorOL1.ResetEventDebounceStatus, timeout=1E-06
          SC_DTC_FRPwrRelsMotorOL1_SetEventStatus: operation=DTC_FRPwrRelsMotorOL1.SetEventStatus, timeout=1E-06
          SC_DTC_FRPwrRelsMotorOL2_GetEventFailed: operation=DTC_FRPwrRelsMotorOL2.GetEventFailed, timeout=1E-06
          SC_DTC_FRPwrRelsMotorOL2_ResetEventDebounceStatus: operation=DTC_FRPwrRelsMotorOL2.ResetEventDebounceStatus, timeout=1E-06
          SC_DTC_FRPwrRelsMotorOL2_SetEventStatus: operation=DTC_FRPwrRelsMotorOL2.SetEventStatus, timeout=1E-06
          SC_DTC_FRPwrRelsMotorOverCurr_GetEventFailed: operation=DTC_FRPwrRelsMotorOverCurr.GetEventFailed, timeout=1E-06
          SC_DTC_FRPwrRelsMotorOverCurr_ResetEventDebounceStatus: operation=DTC_FRPwrRelsMotorOverCurr.ResetEventDebounceStatus, timeout=1E-06
          SC_DTC_FRPwrRelsMotorOverCurr_SetEventStatus: operation=DTC_FRPwrRelsMotorOverCurr.SetEventStatus, timeout=1E-06
          SC_DTC_FRPwrRelsMotorPlusSCB_GetEventFailed: operation=DTC_FRPwrRelsMotorPlusSCB.GetEventFailed, timeout=1E-06
          SC_DTC_FRPwrRelsMotorPlusSCB_ResetEventDebounceStatus: operation=DTC_FRPwrRelsMotorPlusSCB.ResetEventDebounceStatus, timeout=1E-06
          SC_DTC_FRPwrRelsMotorPlusSCB_SetEventStatus: operation=DTC_FRPwrRelsMotorPlusSCB.SetEventStatus, timeout=1E-06
          SC_DTC_FRPwrRelsMotorPlusSCG_GetEventFailed: operation=DTC_FRPwrRelsMotorPlusSCG.GetEventFailed, timeout=1E-06
          SC_DTC_FRPwrRelsMotorPlusSCG_ResetEventDebounceStatus: operation=DTC_FRPwrRelsMotorPlusSCG.ResetEventDebounceStatus, timeout=1E-06
          SC_DTC_FRPwrRelsMotorPlusSCG_SetEventStatus: operation=DTC_FRPwrRelsMotorPlusSCG.SetEventStatus, timeout=1E-06
          SC_DTC_RLChildLockMotorOL_GetEventFailed: operation=DTC_RLChildLockMotorOL.GetEventFailed, timeout=1E-06
          SC_DTC_RLChildLockMotorOL_ResetEventDebounceStatus: operation=DTC_RLChildLockMotorOL.ResetEventDebounceStatus, timeout=1E-06
          SC_DTC_RLChildLockMotorOL_SetEventStatus: operation=DTC_RLChildLockMotorOL.SetEventStatus, timeout=1E-06
          SC_DTC_RLChildLockMotorOverCurr_GetEventFailed: operation=DTC_RLChildLockMotorOverCurr.GetEventFailed, timeout=1E-06
          SC_DTC_RLChildLockMotorOverCurr_ResetEventDebounceStatus: operation=DTC_RLChildLockMotorOverCurr.ResetEventDebounceStatus, timeout=1E-06
          SC_DTC_RLChildLockMotorOverCurr_SetEventStatus: operation=DTC_RLChildLockMotorOverCurr.SetEventStatus, timeout=1E-06
          SC_DTC_RLDoorLockMotorOL_GetEventFailed: operation=DTC_RLDoorLockMotorOL.GetEventFailed, timeout=1E-06
          SC_DTC_RLDoorLockMotorOL_ResetEventDebounceStatus: operation=DTC_RLDoorLockMotorOL.ResetEventDebounceStatus, timeout=1E-06
          SC_DTC_RLDoorLockMotorOL_SetEventStatus: operation=DTC_RLDoorLockMotorOL.SetEventStatus, timeout=1E-06
          SC_DTC_RLDoorLockMotorOverCurr_GetEventFailed: operation=DTC_RLDoorLockMotorOverCurr.GetEventFailed, timeout=1E-06
          SC_DTC_RLDoorLockMotorOverCurr_ResetEventDebounceStatus: operation=DTC_RLDoorLockMotorOverCurr.ResetEventDebounceStatus, timeout=1E-06
          SC_DTC_RLDoorLockMotorOverCurr_SetEventStatus: operation=DTC_RLDoorLockMotorOverCurr.SetEventStatus, timeout=1E-06
          SC_DTC_RLPwrRelsMotorMinusSCB_GetEventFailed: operation=DTC_RLPwrRelsMotorMinusSCB.GetEventFailed, timeout=1E-06
          SC_DTC_RLPwrRelsMotorMinusSCB_ResetEventDebounceStatus: operation=DTC_RLPwrRelsMotorMinusSCB.ResetEventDebounceStatus, timeout=1E-06
          SC_DTC_RLPwrRelsMotorMinusSCB_SetEventStatus: operation=DTC_RLPwrRelsMotorMinusSCB.SetEventStatus, timeout=1E-06
          SC_DTC_RLPwrRelsMotorMinusSCG_GetEventFailed: operation=DTC_RLPwrRelsMotorMinusSCG.GetEventFailed, timeout=1E-06
          SC_DTC_RLPwrRelsMotorMinusSCG_ResetEventDebounceStatus: operation=DTC_RLPwrRelsMotorMinusSCG.ResetEventDebounceStatus, timeout=1E-06
          SC_DTC_RLPwrRelsMotorMinusSCG_SetEventStatus: operation=DTC_RLPwrRelsMotorMinusSCG.SetEventStatus, timeout=1E-06
          SC_DTC_RLPwrRelsMotorOL_GetEventFailed: operation=DTC_RLPwrRelsMotorOL.GetEventFailed, timeout=1E-06
          SC_DTC_RLPwrRelsMotorOL_ResetEventDebounceStatus: operation=DTC_RLPwrRelsMotorOL.ResetEventDebounceStatus, timeout=1E-06
          SC_DTC_RLPwrRelsMotorOL_SetEventStatus: operation=DTC_RLPwrRelsMotorOL.SetEventStatus, timeout=1E-06
          SC_DTC_RLPwrRelsMotorOL1_GetEventFailed: operation=DTC_RLPwrRelsMotorOL1.GetEventFailed, timeout=1E-06
          SC_DTC_RLPwrRelsMotorOL1_ResetEventDebounceStatus: operation=DTC_RLPwrRelsMotorOL1.ResetEventDebounceStatus, timeout=1E-06
          SC_DTC_RLPwrRelsMotorOL1_SetEventStatus: operation=DTC_RLPwrRelsMotorOL1.SetEventStatus, timeout=1E-06
          SC_DTC_RLPwrRelsMotorOL2_GetEventFailed: operation=DTC_RLPwrRelsMotorOL2.GetEventFailed, timeout=1E-06
          SC_DTC_RLPwrRelsMotorOL2_ResetEventDebounceStatus: operation=DTC_RLPwrRelsMotorOL2.ResetEventDebounceStatus, timeout=1E-06
          SC_DTC_RLPwrRelsMotorOL2_SetEventStatus: operation=DTC_RLPwrRelsMotorOL2.SetEventStatus, timeout=1E-06
          SC_DTC_RLPwrRelsMotorOverCurr_GetEventFailed: operation=DTC_RLPwrRelsMotorOverCurr.GetEventFailed, timeout=1E-06
          SC_DTC_RLPwrRelsMotorOverCurr_ResetEventDebounceStatus: operation=DTC_RLPwrRelsMotorOverCurr.ResetEventDebounceStatus, timeout=1E-06
          SC_DTC_RLPwrRelsMotorOverCurr_SetEventStatus: operation=DTC_RLPwrRelsMotorOverCurr.SetEventStatus, timeout=1E-06
          SC_DTC_RLPwrRelsMotorPlusSCB_GetEventFailed: operation=DTC_RLPwrRelsMotorPlusSCB.GetEventFailed, timeout=1E-06
          SC_DTC_RLPwrRelsMotorPlusSCB_ResetEventDebounceStatus: operation=DTC_RLPwrRelsMotorPlusSCB.ResetEventDebounceStatus, timeout=1E-06
          SC_DTC_RLPwrRelsMotorPlusSCB_SetEventStatus: operation=DTC_RLPwrRelsMotorPlusSCB.SetEventStatus, timeout=1E-06
          SC_DTC_RLPwrRelsMotorPlusSCG_GetEventFailed: operation=DTC_RLPwrRelsMotorPlusSCG.GetEventFailed, timeout=1E-06
          SC_DTC_RLPwrRelsMotorPlusSCG_ResetEventDebounceStatus: operation=DTC_RLPwrRelsMotorPlusSCG.ResetEventDebounceStatus, timeout=1E-06
          SC_DTC_RLPwrRelsMotorPlusSCG_SetEventStatus: operation=DTC_RLPwrRelsMotorPlusSCG.SetEventStatus, timeout=1E-06
          SC_DTC_RRChildLockMotorOL_GetEventFailed: operation=DTC_RRChildLockMotorOL.GetEventFailed, timeout=1E-06
          SC_DTC_RRChildLockMotorOL_ResetEventDebounceStatus: operation=DTC_RRChildLockMotorOL.ResetEventDebounceStatus, timeout=1E-06
          SC_DTC_RRChildLockMotorOL_SetEventStatus: operation=DTC_RRChildLockMotorOL.SetEventStatus, timeout=1E-06
          SC_DTC_RRChildLockMotorOverCurr_GetEventFailed: operation=DTC_RRChildLockMotorOverCurr.GetEventFailed, timeout=1E-06
          SC_DTC_RRChildLockMotorOverCurr_ResetEventDebounceStatus: operation=DTC_RRChildLockMotorOverCurr.ResetEventDebounceStatus, timeout=1E-06
          SC_DTC_RRChildLockMotorOverCurr_SetEventStatus: operation=DTC_RRChildLockMotorOverCurr.SetEventStatus, timeout=1E-06
          SC_DTC_RRDoorRockMotorOL_GetEventFailed: operation=DTC_RRDoorLockMotorOL.GetEventFailed, timeout=1E-06
          SC_DTC_RRDoorRockMotorOL_ResetEventDebounceStatus: operation=DTC_RRDoorLockMotorOL.ResetEventDebounceStatus, timeout=1E-06
          SC_DTC_RRDoorRockMotorOL_SetEventStatus: operation=DTC_RRDoorLockMotorOL.SetEventStatus, timeout=1E-06
          SC_DTC_RRDoorRockMotorOverCurr_GetEventFailed: operation=DTC_RRDoorLockMotorOverCurr.GetEventFailed, timeout=1E-06
          SC_DTC_RRDoorRockMotorOverCurr_ResetEventDebounceStatus: operation=DTC_RRDoorLockMotorOverCurr.ResetEventDebounceStatus, timeout=1E-06
          SC_DTC_RRDoorRockMotorOverCurr_SetEventStatus: operation=DTC_RRDoorLockMotorOverCurr.SetEventStatus, timeout=1E-06
          SC_DTC_RRPwrRelsMotorMinusSCB_GetEventFailed: operation=DTC_RRPwrRelsMotorMinusSCB.GetEventFailed, timeout=1E-06
          SC_DTC_RRPwrRelsMotorMinusSCB_ResetEventDebounceStatus: operation=DTC_RRPwrRelsMotorMinusSCB.ResetEventDebounceStatus, timeout=1E-06
          SC_DTC_RRPwrRelsMotorMinusSCB_SetEventStatus: operation=DTC_RRPwrRelsMotorMinusSCB.SetEventStatus, timeout=1E-06
          SC_DTC_RRPwrRelsMotorMinusSCG_GetEventFailed: operation=DTC_RRPwrRelsMotorMinusSCG.GetEventFailed, timeout=1E-06
          SC_DTC_RRPwrRelsMotorMinusSCG_ResetEventDebounceStatus: operation=DTC_RRPwrRelsMotorMinusSCG.ResetEventDebounceStatus, timeout=1E-06
          SC_DTC_RRPwrRelsMotorMinusSCG_SetEventStatus: operation=DTC_RRPwrRelsMotorMinusSCG.SetEventStatus, timeout=1E-06
          SC_DTC_RRPwrRelsMotorOL_GetEventFailed: operation=DTC_RRPwrRelsMotorOL.GetEventFailed, timeout=1E-06
          SC_DTC_RRPwrRelsMotorOL_ResetEventDebounceStatus: operation=DTC_RRPwrRelsMotorOL.ResetEventDebounceStatus, timeout=1E-06
          SC_DTC_RRPwrRelsMotorOL_SetEventStatus: operation=DTC_RRPwrRelsMotorOL.SetEventStatus, timeout=1E-06
          SC_DTC_RRPwrRelsMotorOL1_GetEventFailed: operation=DTC_RRPwrRelsMotorOL1.GetEventFailed, timeout=1E-06
          SC_DTC_RRPwrRelsMotorOL1_ResetEventDebounceStatus: operation=DTC_RRPwrRelsMotorOL1.ResetEventDebounceStatus, timeout=1E-06
          SC_DTC_RRPwrRelsMotorOL1_SetEventStatus: operation=DTC_RRPwrRelsMotorOL1.SetEventStatus, timeout=1E-06
          SC_DTC_RRPwrRelsMotorOL2_GetEventFailed: operation=DTC_RRPwrRelsMotorOL2.GetEventFailed, timeout=1E-06
          SC_DTC_RRPwrRelsMotorOL2_ResetEventDebounceStatus: operation=DTC_RRPwrRelsMotorOL2.ResetEventDebounceStatus, timeout=1E-06
          SC_DTC_RRPwrRelsMotorOL2_SetEventStatus: operation=DTC_RRPwrRelsMotorOL2.SetEventStatus, timeout=1E-06
          SC_DTC_RRPwrRelsMotorOverCurr_GetEventFailed: operation=DTC_RRPwrRelsMotorOverCurr.GetEventFailed, timeout=1E-06
          SC_DTC_RRPwrRelsMotorOverCurr_ResetEventDebounceStatus: operation=DTC_RRPwrRelsMotorOverCurr.ResetEventDebounceStatus, timeout=1E-06
          SC_DTC_RRPwrRelsMotorOverCurr_SetEventStatus: operation=DTC_RRPwrRelsMotorOverCurr.SetEventStatus, timeout=1E-06
          SC_DTC_RRPwrRelsMotorPlusSCB_GetEventFailed: operation=DTC_RRPwrRelsMotorPlusSCB.GetEventFailed, timeout=1E-06
          SC_DTC_RRPwrRelsMotorPlusSCB_ResetEventDebounceStatus: operation=DTC_RRPwrRelsMotorPlusSCB.ResetEventDebounceStatus, timeout=1E-06
          SC_DTC_RRPwrRelsMotorPlusSCB_SetEventStatus: operation=DTC_RRPwrRelsMotorPlusSCB.SetEventStatus, timeout=1E-06
          SC_DTC_RRPwrRelsMotorPlusSCG_GetEventFailed: operation=DTC_RRPwrRelsMotorPlusSCG.GetEventFailed, timeout=1E-06
          SC_DTC_RRPwrRelsMotorPlusSCG_ResetEventDebounceStatus: operation=DTC_RRPwrRelsMotorPlusSCG.ResetEventDebounceStatus, timeout=1E-06
          SC_DTC_RRPwrRelsMotorPlusSCG_SetEventStatus: operation=DTC_RRPwrRelsMotorPlusSCG.SetEventStatus, timeout=1E-06
          SC_IoHwAb_HbrModCtrl_Hbr_SetMod: operation=IoHwAb_HbrModCtrl.Hbr_SetMod, timeout=0
          SC_IoHwAb_HbrPwm_Hbr_SetDuty: operation=IoHwAb_HbrPwm.Hbr_SetDuty, timeout=0
          SC_IoHwAb_IoDiagHbr_Hbr_Get: operation=IoHwAb_IoDiagHbr.Hbr_Get, timeout=0
  swc implementation Lock_DD_Implementation: behavior=Lock_DD_InternalBehavior
    code-descriptors:
      code Default: artifact-descriptors=autosar-engineering-object={short-label=Default, category=SWSRC}
package /UAES/ASW/Units
  unit NoUnit: factor-si-to-unit=1, offset-si-to-unit=0
